AUTOSAR XML (schema 4-2-1)
standard types defined: boolean, float32, sint8, uint16, uint8, boolean_CompuMethod, boolean_DataConstr, float32_DataConstr, sint8_DataConstr, uint16_DataConstr, uint8_DataConstr
package /ComponentTypes
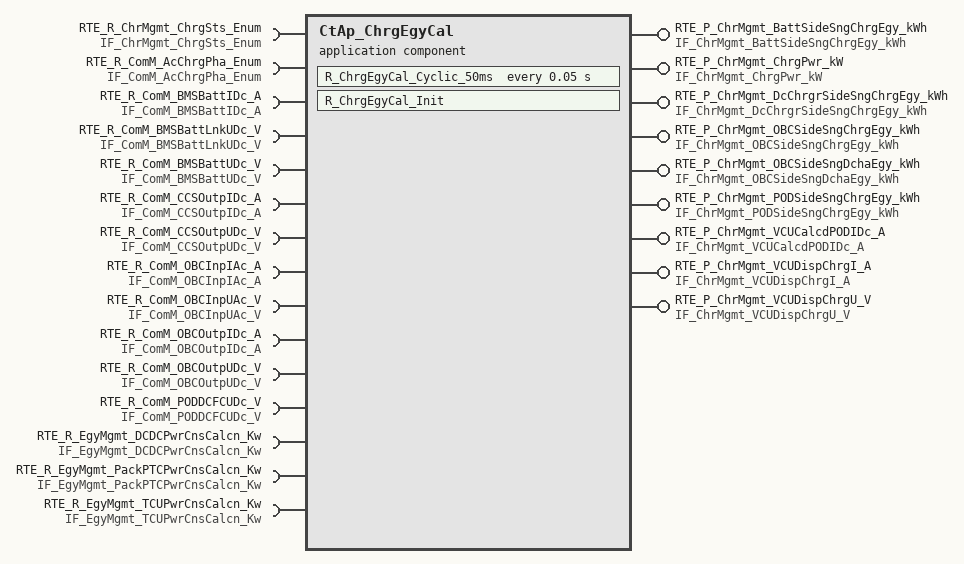
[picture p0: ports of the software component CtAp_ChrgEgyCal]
  application sw component type CtAp_ChrgEgyCal
    9 x provide port:
      RTE_P_ChrMgmt_BattSideSngChrgEgy_kWh: nonqueued-sender-com-spec{data-element=tec_ChrMgmt_BattSideSngChrgEgy_kWh, init-value=0}, provided-interface=IF_ChrMgmt_BattSideSngChrgEgy_kWh
      RTE_P_ChrMgmt_ChrgPwr_kW: nonqueued-sender-com-spec{data-element=tec_ChrMgmt_ChrgPwr_kW, init-value=0}, provided-interface=IF_ChrMgmt_ChrgPwr_kW
      RTE_P_ChrMgmt_DcChrgrSideSngChrgEgy_kWh: nonqueued-sender-com-spec{data-element=tec_ChrMgmt_DcChrgrSideSngChrgEgy_kWh, init-value=0}, provided-interface=IF_ChrMgmt_DcChrgrSideSngChrgEgy_kWh
      RTE_P_ChrMgmt_OBCSideSngChrgEgy_kWh: nonqueued-sender-com-spec{data-element=tec_ChrMgmt_OBCSideSngChrgEgy_kWh, init-value=0}, provided-interface=IF_ChrMgmt_OBCSideSngChrgEgy_kWh
      RTE_P_ChrMgmt_OBCSideSngDchaEgy_kWh: nonqueued-sender-com-spec{data-element=tec_ChrMgmt_OBCSideSngDchaEgy_kWh, init-value=0}, provided-interface=IF_ChrMgmt_OBCSideSngDchaEgy_kWh
      RTE_P_ChrMgmt_PODSideSngChrgEgy_kWh: nonqueued-sender-com-spec{data-element=tec_ChrMgmt_PODSideSngChrgEgy_kWh, init-value=0}, provided-interface=IF_ChrMgmt_PODSideSngChrgEgy_kWh
      RTE_P_ChrMgmt_VCUCalcdPODIDc_A: nonqueued-sender-com-spec{data-element=tec_ChrMgmt_VCUCalcdPODIDc_A, init-value=0}, provided-interface=IF_ChrMgmt_VCUCalcdPODIDc_A
      RTE_P_ChrMgmt_VCUDispChrgI_A: nonqueued-sender-com-spec{data-element=tec_ChrMgmt_VCUDispChrgI_A, init-value=0}, provided-interface=IF_ChrMgmt_VCUDispChrgI_A
      RTE_P_ChrMgmt_VCUDispChrgU_V: nonqueued-sender-com-spec{data-element=tec_ChrMgmt_VCUDispChrgU_V, init-value=0}, provided-interface=IF_ChrMgmt_VCUDispChrgU_V
    15 x require port:
      RTE_R_ChrMgmt_ChrgSts_Enum: nonqueued-receiver-com-spec{data-element=tec_ChrMgmt_ChrgSts_Enum, filter=data-filter-type=ALWAYS, init-value=0}, required-interface=IF_ChrMgmt_ChrgSts_Enum
      RTE_R_ComM_AcChrgPha_Enum: nonqueued-receiver-com-spec{data-element=tec_ComM_AcChrgPha_Enum, filter=data-filter-type=ALWAYS, init-value=0}, required-interface=IF_ComM_AcChrgPha_Enum
      RTE_R_ComM_BMSBattIDc_A: nonqueued-receiver-com-spec{data-element=tec_ComM_BMSBattIDc_A, filter=data-filter-type=ALWAYS, init-value=0}, required-interface=IF_ComM_BMSBattIDc_A
      RTE_R_ComM_BMSBattLnkUDc_V: nonqueued-receiver-com-spec{data-element=tec_ComM_BMSBattLnkUDc_V, filter=data-filter-type=ALWAYS, init-value=0}, required-interface=IF_ComM_BMSBattLnkUDc_V
      RTE_R_ComM_BMSBattUDc_V: nonqueued-receiver-com-spec{data-element=tec_ComM_BMSBattUDc_V, filter=data-filter-type=ALWAYS, init-value=0}, required-interface=IF_ComM_BMSBattUDc_V
      RTE_R_ComM_CCSOutpIDc_A: nonqueued-receiver-com-spec{data-element=tec_ComM_CCSOutpIDc_A, filter=data-filter-type=ALWAYS, init-value=0}, required-interface=IF_ComM_CCSOutpIDc_A
      RTE_R_ComM_CCSOutpUDc_V: nonqueued-receiver-com-spec{data-element=tec_ComM_CCSOutpUDc_V, filter=data-filter-type=ALWAYS, init-value=0}, required-interface=IF_ComM_CCSOutpUDc_V
      RTE_R_ComM_OBCInpIAc_A: nonqueued-receiver-com-spec{data-element=tec_ComM_OBCInpIAc_A, filter=data-filter-type=ALWAYS, init-value=0}, required-interface=IF_ComM_OBCInpIAc_A
      RTE_R_ComM_OBCInpUAc_V: nonqueued-receiver-com-spec{data-element=tec_ComM_OBCInpUAc_V, filter=data-filter-type=ALWAYS, init-value=0}, required-interface=IF_ComM_OBCInpUAc_V
      RTE_R_ComM_OBCOutpIDc_A: nonqueued-receiver-com-spec{data-element=tec_ComM_OBCOutpIDc_A, filter=data-filter-type=ALWAYS, init-value=0}, required-interface=IF_ComM_OBCOutpIDc_A
      RTE_R_ComM_OBCOutpUDc_V: nonqueued-receiver-com-spec{data-element=tec_ComM_OBCOutpUDc_V, filter=data-filter-type=ALWAYS, init-value=0}, required-interface=IF_ComM_OBCOutpUDc_V
      RTE_R_ComM_PODDCFCUDc_V: nonqueued-receiver-com-spec{data-element=tec_ComM_PODDCFCUDc_V, filter=data-filter-type=ALWAYS, init-value=0}, required-interface=IF_ComM_PODDCFCUDc_V
      RTE_R_EgyMgmt_DCDCPwrCnsCalcn_Kw: nonqueued-receiver-com-spec{data-element=tec_EgyMgmt_DCDCPwrCnsCalcn_Kw, filter=data-filter-type=ALWAYS, init-value=0}, required-interface=IF_EgyMgmt_DCDCPwrCnsCalcn_Kw
      RTE_R_EgyMgmt_PackPTCPwrCnsCalcn_Kw: nonqueued-receiver-com-spec{data-element=tec_EgyMgmt_PackPTCPwrCnsCalcn_Kw, filter=data-filter-type=ALWAYS, init-value=0}, required-interface=IF_EgyMgmt_PackPTCPwrCnsCalcn_Kw
      RTE_R_EgyMgmt_TCUPwrCnsCalcn_Kw: nonqueued-receiver-com-spec{data-element=tec_EgyMgmt_TCUPwrCnsCalcn_Kw, filter=data-filter-type=ALWAYS, init-value=0}, required-interface=IF_EgyMgmt_TCUPwrCnsCalcn_Kw
    behavior CtAp_ChrgEgyCal_InternalBehavior
      timing event TMT_R_ChrgEgyCal_Cyclic_50ms: start-on-event=R_ChrgEgyCal_Cyclic_50ms, period=0.05
      init event CtAp_ChrgEgyCal_InitEvent: start-on-event=R_ChrgEgyCal_Init
      runnable R_ChrgEgyCal_Cyclic_50ms
        data-receive-point-by-arguments:
          15 x access:
            REC_RTE_R_ChrMgmt_ChrgSts_Enum_tec_ChrMgmt_ChrgSts_Enum: accessed-variable=RTE_R_ChrMgmt_ChrgSts_Enum.tec_ChrMgmt_ChrgSts_Enum
            REC_RTE_R_ComM_AcChrgPha_Enum_tec_ComM_AcChrgPha_Enum: accessed-variable=RTE_R_ComM_AcChrgPha_Enum.tec_ComM_AcChrgPha_Enum
            REC_RTE_R_ComM_BMSBattIDc_A_tec_ComM_BMSBattIDc_A: accessed-variable=RTE_R_ComM_BMSBattIDc_A.tec_ComM_BMSBattIDc_A
            REC_RTE_R_ComM_BMSBattLnkUDc_V_tec_ComM_BMSBattLnkUDc_V: accessed-variable=RTE_R_ComM_BMSBattLnkUDc_V.tec_ComM_BMSBattLnkUDc_V
            REC_RTE_R_ComM_BMSBattUDc_V_tec_ComM_BMSBattUDc_V: accessed-variable=RTE_R_ComM_BMSBattUDc_V.tec_ComM_BMSBattUDc_V
            REC_RTE_R_ComM_CCSOutpIDc_A_tec_ComM_CCSOutpIDc_A: accessed-variable=RTE_R_ComM_CCSOutpIDc_A.tec_ComM_CCSOutpIDc_A
            REC_RTE_R_ComM_CCSOutpUDc_V_tec_ComM_CCSOutpUDc_V: accessed-variable=RTE_R_ComM_CCSOutpUDc_V.tec_ComM_CCSOutpUDc_V
            REC_RTE_R_ComM_OBCInpIAc_A_tec_ComM_OBCInpIAc_A: accessed-variable=RTE_R_ComM_OBCInpIAc_A.tec_ComM_OBCInpIAc_A
            REC_RTE_R_ComM_OBCInpUAc_V_tec_ComM_OBCInpUAc_V: accessed-variable=RTE_R_ComM_OBCInpUAc_V.tec_ComM_OBCInpUAc_V
            REC_RTE_R_ComM_OBCOutpIDc_A_tec_ComM_OBCOutpIDc_A: accessed-variable=RTE_R_ComM_OBCOutpIDc_A.tec_ComM_OBCOutpIDc_A
            REC_RTE_R_ComM_OBCOutpUDc_V_tec_ComM_OBCOutpUDc_V: accessed-variable=RTE_R_ComM_OBCOutpUDc_V.tec_ComM_OBCOutpUDc_V
            REC_RTE_R_ComM_PODDCFCUDc_V_tec_ComM_PODDCFCUDc_V: accessed-variable=RTE_R_ComM_PODDCFCUDc_V.tec_ComM_PODDCFCUDc_V
            REC_RTE_R_EgyMgmt_DCDCPwrCnsCalcn_Kw_tec_EgyMgmt_DCDCPwrCnsCalcn_Kw: accessed-variable=RTE_R_EgyMgmt_DCDCPwrCnsCalcn_Kw.tec_EgyMgmt_DCDCPwrCnsCalcn_Kw
            REC_RTE_R_EgyMgmt_PackPTCPwrCnsCalcn_Kw_tec_EgyMgmt_PackPTCPwrCnsCalcn_Kw: accessed-variable=RTE_R_EgyMgmt_PackPTCPwrCnsCalcn_Kw.tec_EgyMgmt_PackPTCPwrCnsCalcn_Kw
            REC_RTE_R_EgyMgmt_TCUPwrCnsCalcn_Kw_tec_EgyMgmt_TCUPwrCnsCalcn_Kw: accessed-variable=RTE_R_EgyMgmt_TCUPwrCnsCalcn_Kw.tec_EgyMgmt_TCUPwrCnsCalcn_Kw
        data-send-points:
          9 x access:
            SEND_RTE_P_ChrMgmt_BattSideSngChrgEgy_kWh_tec_ChrMgmt_BattSideSngChrgEgy_kWh: accessed-variable=RTE_P_ChrMgmt_BattSideSngChrgEgy_kWh.tec_ChrMgmt_BattSideSngChrgEgy_kWh
            SEND_RTE_P_ChrMgmt_ChrgPwr_kW_tec_ChrMgmt_ChrgPwr_kW: accessed-variable=RTE_P_ChrMgmt_ChrgPwr_kW.tec_ChrMgmt_ChrgPwr_kW
            SEND_RTE_P_ChrMgmt_DcChrgrSideSngChrgEgy_kWh_tec_ChrMgmt_DcChrgrSideSngChrgEgy_kWh: accessed-variable=RTE_P_ChrMgmt_DcChrgrSideSngChrgEgy_kWh.tec_ChrMgmt_DcChrgrSideSngChrgEgy_kWh
            SEND_RTE_P_ChrMgmt_OBCSideSngChrgEgy_kWh_tec_ChrMgmt_OBCSideSngChrgEgy_kWh: accessed-variable=RTE_P_ChrMgmt_OBCSideSngChrgEgy_kWh.tec_ChrMgmt_OBCSideSngChrgEgy_kWh
            SEND_RTE_P_ChrMgmt_OBCSideSngDchaEgy_kWh_tec_ChrMgmt_OBCSideSngDchaEgy_kWh: accessed-variable=RTE_P_ChrMgmt_OBCSideSngDchaEgy_kWh.tec_ChrMgmt_OBCSideSngDchaEgy_kWh
            SEND_RTE_P_ChrMgmt_PODSideSngChrgEgy_kWh_tec_ChrMgmt_PODSideSngChrgEgy_kWh: accessed-variable=RTE_P_ChrMgmt_PODSideSngChrgEgy_kWh.tec_ChrMgmt_PODSideSngChrgEgy_kWh
            SEND_RTE_P_ChrMgmt_VCUCalcdPODIDc_A_tec_ChrMgmt_VCUCalcdPODIDc_A: accessed-variable=RTE_P_ChrMgmt_VCUCalcdPODIDc_A.tec_ChrMgmt_VCUCalcdPODIDc_A
            SEND_RTE_P_ChrMgmt_VCUDispChrgI_A_tec_ChrMgmt_VCUDispChrgI_A: accessed-variable=RTE_P_ChrMgmt_VCUDispChrgI_A.tec_ChrMgmt_VCUDispChrgI_A
            SEND_RTE_P_ChrMgmt_VCUDispChrgU_V_tec_ChrMgmt_VCUDispChrgU_V: accessed-variable=RTE_P_ChrMgmt_VCUDispChrgU_V.tec_ChrMgmt_VCUDispChrgU_V
      runnable R_ChrgEgyCal_Init
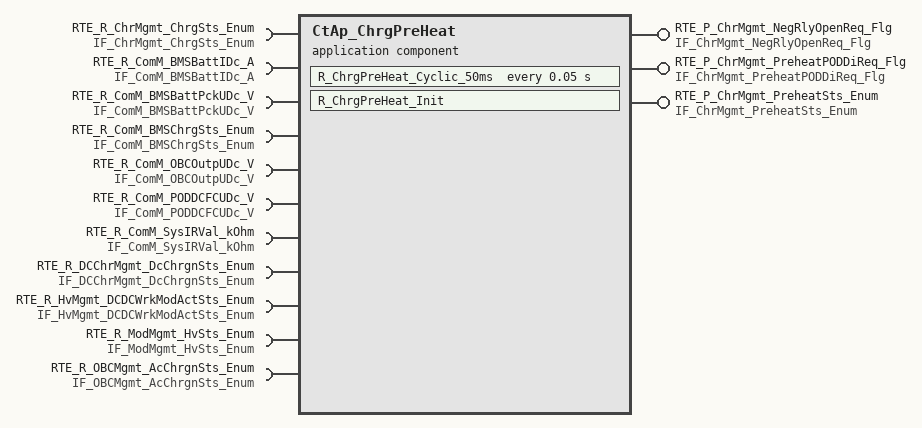
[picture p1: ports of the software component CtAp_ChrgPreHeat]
  application sw component type CtAp_ChrgPreHeat
    provide port RTE_P_ChrMgmt_NegRlyOpenReq_Flg: nonqueued-sender-com-spec{data-element=tec_ChrMgmt_NegRlyOpenReq_Flg, init-value=0}, provided-interface=IF_ChrMgmt_NegRlyOpenReq_Flg
    provide port RTE_P_ChrMgmt_PreheatPODDiReq_Flg: nonqueued-sender-com-spec{data-element=tec_ChrMgmt_PreheatPODDiReq_Flg, init-value=0}, provided-interface=IF_ChrMgmt_PreheatPODDiReq_Flg
    provide port RTE_P_ChrMgmt_PreheatSts_Enum: nonqueued-sender-com-spec{data-element=tec_ChrMgmt_PreheatSts_Enum, init-value=0}, provided-interface=IF_ChrMgmt_PreheatSts_Enum
    11 x require port:
      RTE_R_ChrMgmt_ChrgSts_Enum: nonqueued-receiver-com-spec{data-element=tec_ChrMgmt_ChrgSts_Enum, filter=data-filter-type=ALWAYS, init-value=0}, required-interface=IF_ChrMgmt_ChrgSts_Enum
      RTE_R_ComM_BMSBattIDc_A: nonqueued-receiver-com-spec{data-element=tec_ComM_BMSBattIDc_A, filter=data-filter-type=ALWAYS, init-value=0}, required-interface=IF_ComM_BMSBattIDc_A
      RTE_R_ComM_BMSBattPckUDc_V: nonqueued-receiver-com-spec{data-element=tec_ComM_BMSBattPckUDc_V, filter=data-filter-type=ALWAYS, init-value=0}, required-interface=IF_ComM_BMSBattPckUDc_V
      RTE_R_ComM_BMSChrgSts_Enum: nonqueued-receiver-com-spec{data-element=tec_ComM_BMSChrgSts_Enum, filter=data-filter-type=ALWAYS, init-value=0}, required-interface=IF_ComM_BMSChrgSts_Enum
      RTE_R_ComM_OBCOutpUDc_V: nonqueued-receiver-com-spec{data-element=tec_ComM_OBCOutpUDc_V, filter=data-filter-type=ALWAYS, init-value=0}, required-interface=IF_ComM_OBCOutpUDc_V
      RTE_R_ComM_PODDCFCUDc_V: nonqueued-receiver-com-spec{data-element=tec_ComM_PODDCFCUDc_V, filter=data-filter-type=ALWAYS, init-value=0}, required-interface=IF_ComM_PODDCFCUDc_V
      RTE_R_ComM_SysIRVal_kOhm: nonqueued-receiver-com-spec{data-element=tec_ComM_SysIRVal_kOhm, filter=data-filter-type=ALWAYS, init-value=0}, required-interface=IF_ComM_SysIRVal_kOhm
      RTE_R_DCChrMgmt_DcChrgnSts_Enum: nonqueued-receiver-com-spec{data-element=tec_DCChrMgmt_DcChrgnSts_Enum, filter=data-filter-type=ALWAYS, init-value=0}, required-interface=IF_DCChrMgmt_DcChrgnSts_Enum
      RTE_R_HvMgmt_DCDCWrkModActSts_Enum: nonqueued-receiver-com-spec{data-element=tec_HvMgmt_DCDCWrkModActSts_Enum, filter=data-filter-type=ALWAYS, init-value=0}, required-interface=IF_HvMgmt_DCDCWrkModActSts_Enum
      RTE_R_ModMgmt_HvSts_Enum: nonqueued-receiver-com-spec{data-element=tec_ModMgmt_HvSts_Enum, filter=data-filter-type=ALWAYS, init-value=0}, required-interface=IF_ModMgmt_HvSts_Enum
      RTE_R_OBCMgmt_AcChrgnSts_Enum: nonqueued-receiver-com-spec{data-element=tec_OBCMgmt_AcChrgnSts_Enum, filter=data-filter-type=ALWAYS, init-value=0}, required-interface=IF_OBCMgmt_AcChrgnSts_Enum
    behavior CtAp_ChrgPreHeat_InternalBehavior
      timing event TMT_R_ChrgPreHeat_Cyclic_50ms: start-on-event=R_ChrgPreHeat_Cyclic_50ms, period=0.05
      init event CtAp_ChrgPreHeat_InitEvent: start-on-event=R_ChrgPreHeat_Init
      runnable R_ChrgPreHeat_Cyclic_50ms
        data-receive-point-by-arguments:
          11 x access:
            REC_RTE_R_ChrMgmt_ChrgSts_Enum_tec_ChrMgmt_ChrgSts_Enum: accessed-variable=RTE_R_ChrMgmt_ChrgSts_Enum.tec_ChrMgmt_ChrgSts_Enum
            REC_RTE_R_ComM_BMSBattIDc_A_tec_ComM_BMSBattIDc_A: accessed-variable=RTE_R_ComM_BMSBattIDc_A.tec_ComM_BMSBattIDc_A
            REC_RTE_R_ComM_BMSBattPckUDc_V_tec_ComM_BMSBattPckUDc_V: accessed-variable=RTE_R_ComM_BMSBattPckUDc_V.tec_ComM_BMSBattPckUDc_V
            REC_RTE_R_ComM_BMSChrgSts_Enum_tec_ComM_BMSChrgSts_Enum: accessed-variable=RTE_R_ComM_BMSChrgSts_Enum.tec_ComM_BMSChrgSts_Enum
            REC_RTE_R_ComM_OBCOutpUDc_V_tec_ComM_OBCOutpUDc_V: accessed-variable=RTE_R_ComM_OBCOutpUDc_V.tec_ComM_OBCOutpUDc_V
            REC_RTE_R_ComM_PODDCFCUDc_V_tec_ComM_PODDCFCUDc_V: accessed-variable=RTE_R_ComM_PODDCFCUDc_V.tec_ComM_PODDCFCUDc_V
            REC_RTE_R_ComM_SysIRVal_kOhm_tec_ComM_SysIRVal_kOhm: accessed-variable=RTE_R_ComM_SysIRVal_kOhm.tec_ComM_SysIRVal_kOhm
            REC_RTE_R_DCChrMgmt_DcChrgnSts_Enum_tec_DCChrMgmt_DcChrgnSts_Enum: accessed-variable=RTE_R_DCChrMgmt_DcChrgnSts_Enum.tec_DCChrMgmt_DcChrgnSts_Enum
            REC_RTE_R_HvMgmt_DCDCWrkModActSts_Enum_tec_HvMgmt_DCDCWrkModActSts_Enum: accessed-variable=RTE_R_HvMgmt_DCDCWrkModActSts_Enum.tec_HvMgmt_DCDCWrkModActSts_Enum
            REC_RTE_R_ModMgmt_HvSts_Enum_tec_ModMgmt_HvSts_Enum: accessed-variable=RTE_R_ModMgmt_HvSts_Enum.tec_ModMgmt_HvSts_Enum
            REC_RTE_R_OBCMgmt_AcChrgnSts_Enum_tec_OBCMgmt_AcChrgnSts_Enum: accessed-variable=RTE_R_OBCMgmt_AcChrgnSts_Enum.tec_OBCMgmt_AcChrgnSts_Enum
        data-send-points:
          access SEND_RTE_P_ChrMgmt_NegRlyOpenReq_Flg_tec_ChrMgmt_NegRlyOpenReq_Flg: accessed-variable=RTE_P_ChrMgmt_NegRlyOpenReq_Flg.tec_ChrMgmt_NegRlyOpenReq_Flg
          access SEND_RTE_P_ChrMgmt_PreheatPODDiReq_Flg_tec_ChrMgmt_PreheatPODDiReq_Flg: accessed-variable=RTE_P_ChrMgmt_PreheatPODDiReq_Flg.tec_ChrMgmt_PreheatPODDiReq_Flg
          access SEND_RTE_P_ChrMgmt_PreheatSts_Enum_tec_ChrMgmt_PreheatSts_Enum: accessed-variable=RTE_P_ChrMgmt_PreheatSts_Enum.tec_ChrMgmt_PreheatSts_Enum
      runnable R_ChrgPreHeat_Init
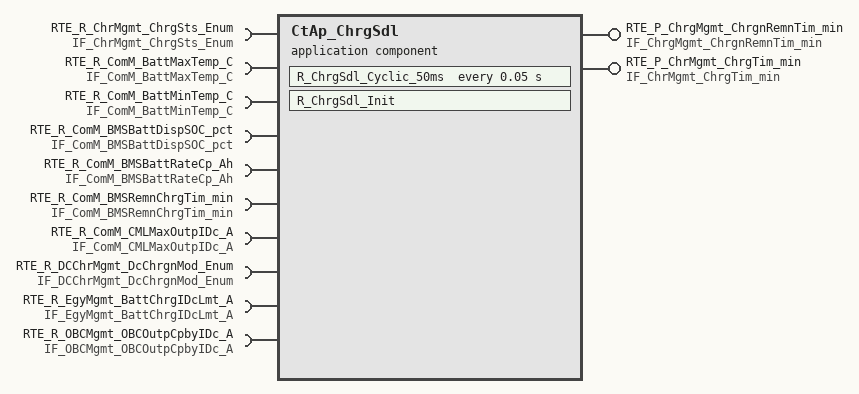
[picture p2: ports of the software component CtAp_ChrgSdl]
  application sw component type CtAp_ChrgSdl
    provide port RTE_P_ChrgMgmt_ChrgnRemnTim_min: nonqueued-sender-com-spec{data-element=tec_ChrgMgmt_ChrgnRemnTim_min, init-value=0}, provided-interface=IF_ChrgMgmt_ChrgnRemnTim_min
    provide port RTE_P_ChrMgmt_ChrgTim_min: nonqueued-sender-com-spec{data-element=tec_ChrMgmt_ChrgTim_min, init-value=0}, provided-interface=IF_ChrMgmt_ChrgTim_min
    10 x require port:
      RTE_R_ChrMgmt_ChrgSts_Enum: nonqueued-receiver-com-spec{data-element=tec_ChrMgmt_ChrgSts_Enum, filter=data-filter-type=ALWAYS, init-value=0}, required-interface=IF_ChrMgmt_ChrgSts_Enum
      RTE_R_ComM_BattMaxTemp_C: nonqueued-receiver-com-spec{data-element=tec_ComM_BMSBattMaxTemp_C, filter=data-filter-type=ALWAYS, init-value=0}, required-interface=IF_ComM_BattMaxTemp_C
      RTE_R_ComM_BattMinTemp_C: nonqueued-receiver-com-spec{data-element=tec_ComM_BMSBattMinTemp_C, filter=data-filter-type=ALWAYS, init-value=0}, required-interface=IF_ComM_BattMinTemp_C
      RTE_R_ComM_BMSBattDispSOC_pct: nonqueued-receiver-com-spec{data-element=tec_ComM_BMSBattDispSOC_pct, filter=data-filter-type=ALWAYS, init-value=0}, required-interface=IF_ComM_BMSBattDispSOC_pct
      RTE_R_ComM_BMSBattRateCp_Ah: nonqueued-receiver-com-spec{data-element=tec_ComM_BMSBattRateCp_Ah, filter=data-filter-type=ALWAYS, init-value=0}, required-interface=IF_ComM_BMSBattRateCp_Ah
      RTE_R_ComM_BMSRemnChrgTim_min: nonqueued-receiver-com-spec{data-element=tec_ComM_BMSRemnChrgTim_min, filter=data-filter-type=ALWAYS, init-value=0}, required-interface=IF_ComM_BMSRemnChrgTim_min
      RTE_R_ComM_CMLMaxOutpIDc_A: nonqueued-receiver-com-spec{data-element=tec_ComM_CMLMaxOutpIDc_A, filter=data-filter-type=ALWAYS, init-value=0}, required-interface=IF_ComM_CMLMaxOutpIDc_A
      RTE_R_DCChrMgmt_DcChrgnMod_Enum: nonqueued-receiver-com-spec{data-element=tec_DCChrMgmt_DcChrgnMod_Enum, filter=data-filter-type=ALWAYS, init-value=0}, required-interface=IF_DCChrMgmt_DcChrgnMod_Enum
      RTE_R_EgyMgmt_BattChrgIDcLmt_A: nonqueued-receiver-com-spec{data-element=tec_EgyMgmt_BattChrgIDcLmt_A, filter=data-filter-type=ALWAYS, init-value=0}, required-interface=IF_EgyMgmt_BattChrgIDcLmt_A
      RTE_R_OBCMgmt_OBCOutpCpbyIDc_A: nonqueued-receiver-com-spec{data-element=tec_OBCMgmt_OBCOutpCpbyIDc_A, filter=data-filter-type=ALWAYS, init-value=0}, required-interface=IF_OBCMgmt_OBCOutpCpbyIDc_A
    behavior CtAp_ChrgSdl_InternalBehavior
      timing event TMT_R_ChrgSdl_Cyclic_50ms: start-on-event=R_ChrgSdl_Cyclic_50ms, period=0.05
      init event CtAp_ChrgSdl_InitEvent: start-on-event=R_ChrgSdl_Init
      runnable R_ChrgSdl_Cyclic_50ms
        data-receive-point-by-arguments:
          10 x access:
            REC_RTE_R_ChrMgmt_ChrgSts_Enum_tec_ChrMgmt_ChrgSts_Enum: accessed-variable=RTE_R_ChrMgmt_ChrgSts_Enum.tec_ChrMgmt_ChrgSts_Enum
            REC_RTE_R_ComM_BattMaxTemp_C_tec_ComM_BMSBattMaxTemp_C: accessed-variable=RTE_R_ComM_BattMaxTemp_C.tec_ComM_BMSBattMaxTemp_C
            REC_RTE_R_ComM_BattMinTemp_C_tec_ComM_BMSBattMinTemp_C: accessed-variable=RTE_R_ComM_BattMinTemp_C.tec_ComM_BMSBattMinTemp_C
            REC_RTE_R_ComM_BMSBattDispSOC_pct_tec_ComM_BMSBattDispSOC_pct: accessed-variable=RTE_R_ComM_BMSBattDispSOC_pct.tec_ComM_BMSBattDispSOC_pct
            REC_RTE_R_ComM_BMSBattRateCp_Ah_tec_ComM_BMSBattRateCp_Ah: accessed-variable=RTE_R_ComM_BMSBattRateCp_Ah.tec_ComM_BMSBattRateCp_Ah
            REC_RTE_R_ComM_BMSRemnChrgTim_min_tec_ComM_BMSRemnChrgTim_min: accessed-variable=RTE_R_ComM_BMSRemnChrgTim_min.tec_ComM_BMSRemnChrgTim_min
            REC_RTE_R_ComM_CMLMaxOutpIDc_A_tec_ComM_CMLMaxOutpIDc_A: accessed-variable=RTE_R_ComM_CMLMaxOutpIDc_A.tec_ComM_CMLMaxOutpIDc_A
            REC_RTE_R_DCChrMgmt_DcChrgnMod_Enum_tec_DCChrMgmt_DcChrgnMod_Enum: accessed-variable=RTE_R_DCChrMgmt_DcChrgnMod_Enum.tec_DCChrMgmt_DcChrgnMod_Enum
            REC_RTE_R_EgyMgmt_BattChrgIDcLmt_A_tec_EgyMgmt_BattChrgIDcLmt_A: accessed-variable=RTE_R_EgyMgmt_BattChrgIDcLmt_A.tec_EgyMgmt_BattChrgIDcLmt_A
            REC_RTE_R_OBCMgmt_OBCOutpCpbyIDc_A_tec_OBCMgmt_OBCOutpCpbyIDc_A: accessed-variable=RTE_R_OBCMgmt_OBCOutpCpbyIDc_A.tec_OBCMgmt_OBCOutpCpbyIDc_A
        data-send-points:
          access SEND_RTE_P_ChrgMgmt_ChrgnRemnTim_min_tec_ChrgMgmt_ChrgnRemnTim_min: accessed-variable=RTE_P_ChrgMgmt_ChrgnRemnTim_min.tec_ChrgMgmt_ChrgnRemnTim_min
          access SEND_RTE_P_ChrMgmt_ChrgTim_min_tec_ChrMgmt_ChrgTim_min: accessed-variable=RTE_P_ChrMgmt_ChrgTim_min.tec_ChrMgmt_ChrgTim_min
      runnable R_ChrgSdl_Init
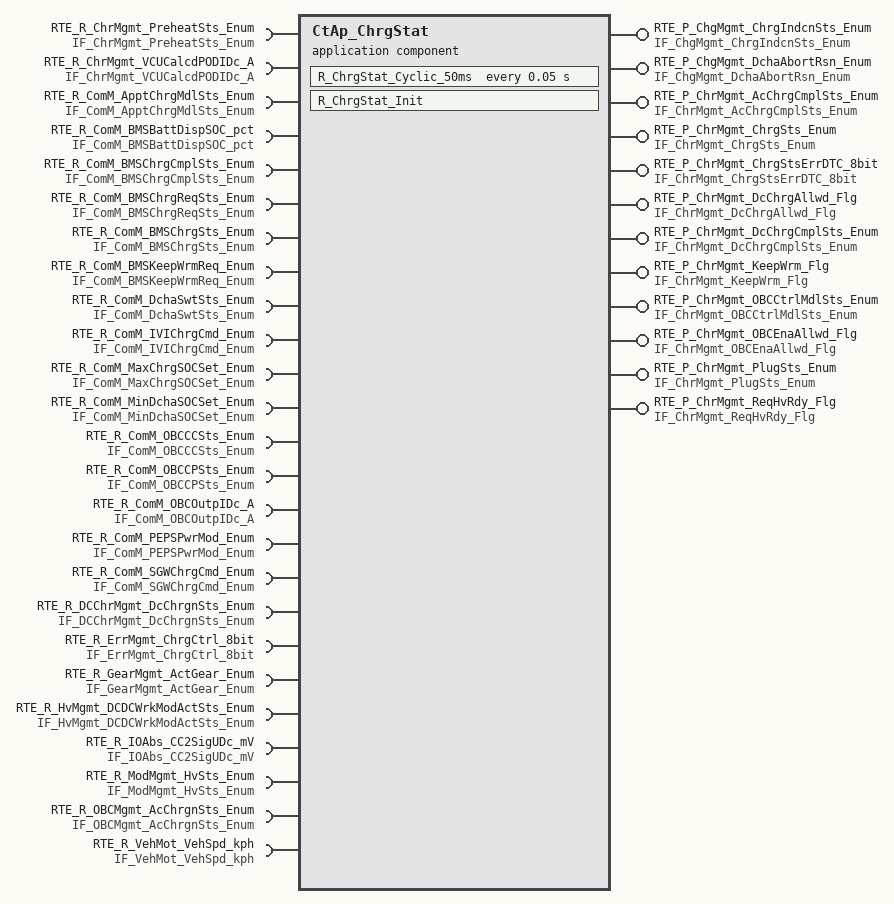
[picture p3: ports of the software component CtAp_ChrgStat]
  application sw component type CtAp_ChrgStat
    12 x provide port:
      RTE_P_ChgMgmt_ChrgIndcnSts_Enum: nonqueued-sender-com-spec{data-element=tec_ChgMgmt_ChrgIndcnSts_Enum, init-value=0}, provided-interface=IF_ChgMgmt_ChrgIndcnSts_Enum
      RTE_P_ChgMgmt_DchaAbortRsn_Enum: nonqueued-sender-com-spec{data-element=tec_ChgMgmt_DchaAbortRsn_Enum, init-value=0}, provided-interface=IF_ChgMgmt_DchaAbortRsn_Enum
      RTE_P_ChrMgmt_AcChrgCmplSts_Enum: nonqueued-sender-com-spec{data-element=tec_ChrMgmt_AcChrgCmplSts_Enum, init-value=0}, provided-interface=IF_ChrMgmt_AcChrgCmplSts_Enum
      RTE_P_ChrMgmt_ChrgSts_Enum: nonqueued-sender-com-spec{data-element=tec_ChrMgmt_ChrgSts_Enum, init-value=0}, provided-interface=IF_ChrMgmt_ChrgSts_Enum
      RTE_P_ChrMgmt_ChrgStsErrDTC_8bit: nonqueued-sender-com-spec{data-element=tec_ChrMgmt_ChrgStsErrDTC_8bit, init-value=0}, provided-interface=IF_ChrMgmt_ChrgStsErrDTC_8bit
      RTE_P_ChrMgmt_DcChrgAllwd_Flg: nonqueued-sender-com-spec{data-element=tec_ChrMgmt_DcChrgAllwd_Flg, init-value=0}, provided-interface=IF_ChrMgmt_DcChrgAllwd_Flg
      RTE_P_ChrMgmt_DcChrgCmplSts_Enum: nonqueued-sender-com-spec{data-element=tec_ChrMgmt_DcChrgCmplSts_Enum, init-value=0}, provided-interface=IF_ChrMgmt_DcChrgCmplSts_Enum
      RTE_P_ChrMgmt_KeepWrm_Flg: nonqueued-sender-com-spec{data-element=tec_ChrMgmt_KeepWrm_Flg, init-value=0}, provided-interface=IF_ChrMgmt_KeepWrm_Flg
      RTE_P_ChrMgmt_OBCCtrlMdlSts_Enum: nonqueued-sender-com-spec{data-element=tec_ChrMgmt_OBCCtrlMdlSts_Enum, init-value=0}, provided-interface=IF_ChrMgmt_OBCCtrlMdlSts_Enum
      RTE_P_ChrMgmt_OBCEnaAllwd_Flg: nonqueued-sender-com-spec{data-element=tec_ChrMgmt_OBCEnaAllwd_Flg, init-value=0}, provided-interface=IF_ChrMgmt_OBCEnaAllwd_Flg
      RTE_P_ChrMgmt_PlugSts_Enum: nonqueued-sender-com-spec{data-element=tec_ChrMgmt_PlugSts_Enum, init-value=0}, provided-interface=IF_ChrMgmt_PlugSts_Enum
      RTE_P_ChrMgmt_ReqHvRdy_Flg: nonqueued-sender-com-spec{data-element=tec_ChrMgmt_ReqHvRdy_Flg, init-value=0}, provided-interface=IF_ChrMgmt_ReqHvRdy_Flg
    25 x require port:
      RTE_R_ChrMgmt_PreheatSts_Enum: nonqueued-receiver-com-spec{data-element=tec_ChrMgmt_PreheatSts_Enum, filter=data-filter-type=ALWAYS, init-value=0}, required-interface=IF_ChrMgmt_PreheatSts_Enum
      RTE_R_ChrMgmt_VCUCalcdPODIDc_A: nonqueued-receiver-com-spec{data-element=tec_ChrMgmt_VCUCalcdPODIDc_A, filter=data-filter-type=ALWAYS, init-value=0}, required-interface=IF_ChrMgmt_VCUCalcdPODIDc_A
      RTE_R_ComM_ApptChrgMdlSts_Enum: nonqueued-receiver-com-spec{data-element=tec_ComM_ApptChrgMdlSts_Enum, filter=data-filter-type=ALWAYS, init-value=0}, required-interface=IF_ComM_ApptChrgMdlSts_Enum
      RTE_R_ComM_BMSBattDispSOC_pct: nonqueued-receiver-com-spec{data-element=tec_ComM_BMSBattDispSOC_pct, filter=data-filter-type=ALWAYS, init-value=0}, required-interface=IF_ComM_BMSBattDispSOC_pct
      RTE_R_ComM_BMSChrgCmplSts_Enum: nonqueued-receiver-com-spec{data-element=tec_ComM_BMSChrgCmplSts_Enum, filter=data-filter-type=ALWAYS, init-value=0}, required-interface=IF_ComM_BMSChrgCmplSts_Enum
      RTE_R_ComM_BMSChrgReqSts_Enum: nonqueued-receiver-com-spec{data-element=tec_ComM_BMSChrgReqSts_Enum, filter=data-filter-type=ALWAYS, init-value=0}, required-interface=IF_ComM_BMSChrgReqSts_Enum
      RTE_R_ComM_BMSChrgSts_Enum: nonqueued-receiver-com-spec{data-element=tec_ComM_BMSChrgSts_Enum, filter=data-filter-type=ALWAYS, init-value=0}, required-interface=IF_ComM_BMSChrgSts_Enum
      RTE_R_ComM_BMSKeepWrmReq_Enum: nonqueued-receiver-com-spec{data-element=tec_ComM_BMSKeepWrmReq_Enum, filter=data-filter-type=ALWAYS, init-value=0}, required-interface=IF_ComM_BMSKeepWrmReq_Enum
      RTE_R_ComM_DchaSwtSts_Enum: nonqueued-receiver-com-spec{data-element=tec_ComM_DchaSwtSts_Enum, filter=data-filter-type=ALWAYS, init-value=0}, required-interface=IF_ComM_DchaSwtSts_Enum
      RTE_R_ComM_IVIChrgCmd_Enum: nonqueued-receiver-com-spec{data-element=tec_ComM_IVIChrgCmd_Enum, filter=data-filter-type=ALWAYS, init-value=0}, required-interface=IF_ComM_IVIChrgCmd_Enum
      RTE_R_ComM_MaxChrgSOCSet_Enum: nonqueued-receiver-com-spec{data-element=tec_ComM_MaxChrgSOCSet_Enum, filter=data-filter-type=ALWAYS, init-value=0}, required-interface=IF_ComM_MaxChrgSOCSet_Enum
      RTE_R_ComM_MinDchaSOCSet_Enum: nonqueued-receiver-com-spec{data-element=tec_ComM_MinDchaSOCSet_Enum, filter=data-filter-type=ALWAYS, init-value=0}, required-interface=IF_ComM_MinDchaSOCSet_Enum
      RTE_R_ComM_OBCCCSts_Enum: nonqueued-receiver-com-spec{data-element=tec_ComM_OBCCCSts_Enum, filter=data-filter-type=ALWAYS, init-value=0}, required-interface=IF_ComM_OBCCCSts_Enum
      RTE_R_ComM_OBCCPSts_Enum: nonqueued-receiver-com-spec{data-element=tec_ComM_OBCCPSts_Enum, filter=data-filter-type=ALWAYS, init-value=0}, required-interface=IF_ComM_OBCCPSts_Enum
      RTE_R_ComM_OBCOutpIDc_A: nonqueued-receiver-com-spec{data-element=tec_ComM_OBCOutpIDc_A, filter=data-filter-type=ALWAYS, init-value=0}, required-interface=IF_ComM_OBCOutpIDc_A
      RTE_R_ComM_PEPSPwrMod_Enum: nonqueued-receiver-com-spec{data-element=tec_ComM_PEPSPwrMod_Enum, filter=data-filter-type=ALWAYS, init-value=0}, required-interface=IF_ComM_PEPSPwrMod_Enum
      RTE_R_ComM_SGWChrgCmd_Enum: nonqueued-receiver-com-spec{data-element=tec_ComM_SGWChrgCmd_Enum, filter=data-filter-type=ALWAYS, init-value=0}, required-interface=IF_ComM_SGWChrgCmd_Enum
      RTE_R_DCChrMgmt_DcChrgnSts_Enum: nonqueued-receiver-com-spec{data-element=tec_DCChrMgmt_DcChrgnSts_Enum, filter=data-filter-type=ALWAYS, init-value=0}, required-interface=IF_DCChrMgmt_DcChrgnSts_Enum
      RTE_R_ErrMgmt_ChrgCtrl_8bit: nonqueued-receiver-com-spec{data-element=tec_ErrMgmt_ChrgCtrl_8bit, filter=data-filter-type=ALWAYS, init-value=0}, required-interface=IF_ErrMgmt_ChrgCtrl_8bit
      RTE_R_GearMgmt_ActGear_Enum: nonqueued-receiver-com-spec{data-element=tec_GearMgmt_ActGear_Enum, filter=data-filter-type=ALWAYS, init-value=0}, required-interface=IF_GearMgmt_ActGear_Enum
      RTE_R_HvMgmt_DCDCWrkModActSts_Enum: nonqueued-receiver-com-spec{data-element=tec_HvMgmt_DCDCWrkModActSts_Enum, filter=data-filter-type=ALWAYS, init-value=0}, required-interface=IF_HvMgmt_DCDCWrkModActSts_Enum
      RTE_R_IOAbs_CC2SigUDc_mV: nonqueued-receiver-com-spec{data-element=tec_IOAbs_CC2SigUDc_mV, filter=data-filter-type=ALWAYS, init-value=0}, required-interface=IF_IOAbs_CC2SigUDc_mV
      RTE_R_ModMgmt_HvSts_Enum: nonqueued-receiver-com-spec{data-element=tec_ModMgmt_HvSts_Enum, filter=data-filter-type=ALWAYS, init-value=0}, required-interface=IF_ModMgmt_HvSts_Enum
      RTE_R_OBCMgmt_AcChrgnSts_Enum: nonqueued-receiver-com-spec{data-element=tec_OBCMgmt_AcChrgnSts_Enum, filter=data-filter-type=ALWAYS, init-value=0}, required-interface=IF_OBCMgmt_AcChrgnSts_Enum
      RTE_R_VehMot_VehSpd_kph: nonqueued-receiver-com-spec{data-element=tec_VehMot_VehSpd_kph, filter=data-filter-type=ALWAYS, init-value=0}, required-interface=IF_VehMot_VehSpd_kph
    behavior CtAp_ChrgStat_InternalBehavior
      timing event TMT_R_ChrgStat_Cyclic_50ms: start-on-event=R_ChrgStat_Cyclic_50ms, period=0.05
      init event CtAp_ChrgStat_InitEvent: start-on-event=R_ChrgStat_Init
      runnable R_ChrgStat_Cyclic_50ms
        data-receive-point-by-arguments:
          25 x access:
            REC_RTE_R_ChrMgmt_PreheatSts_Enum_tec_ChrMgmt_PreheatSts_Enum: accessed-variable=RTE_R_ChrMgmt_PreheatSts_Enum.tec_ChrMgmt_PreheatSts_Enum
            REC_RTE_R_ChrMgmt_VCUCalcdPODIDc_A_tec_ChrMgmt_VCUCalcdPODIDc_A: accessed-variable=RTE_R_ChrMgmt_VCUCalcdPODIDc_A.tec_ChrMgmt_VCUCalcdPODIDc_A
            REC_RTE_R_ComM_ApptChrgMdlSts_Enum_tec_ComM_ApptChrgMdlSts_Enum: accessed-variable=RTE_R_ComM_ApptChrgMdlSts_Enum.tec_ComM_ApptChrgMdlSts_Enum
            REC_RTE_R_ComM_BMSBattDispSOC_pct_tec_ComM_BMSBattDispSOC_pct: accessed-variable=RTE_R_ComM_BMSBattDispSOC_pct.tec_ComM_BMSBattDispSOC_pct
            REC_RTE_R_ComM_BMSChrgCmplSts_Enum_tec_ComM_BMSChrgCmplSts_Enum: accessed-variable=RTE_R_ComM_BMSChrgCmplSts_Enum.tec_ComM_BMSChrgCmplSts_Enum
            REC_RTE_R_ComM_BMSChrgReqSts_Enum_tec_ComM_BMSChrgReqSts_Enum: accessed-variable=RTE_R_ComM_BMSChrgReqSts_Enum.tec_ComM_BMSChrgReqSts_Enum
            REC_RTE_R_ComM_BMSChrgSts_Enum_tec_ComM_BMSChrgSts_Enum: accessed-variable=RTE_R_ComM_BMSChrgSts_Enum.tec_ComM_BMSChrgSts_Enum
            REC_RTE_R_ComM_BMSKeepWrmReq_Enum_tec_ComM_BMSKeepWrmReq_Enum: accessed-variable=RTE_R_ComM_BMSKeepWrmReq_Enum.tec_ComM_BMSKeepWrmReq_Enum
            REC_RTE_R_ComM_DchaSwtSts_Enum_tec_ComM_DchaSwtSts_Enum: accessed-variable=RTE_R_ComM_DchaSwtSts_Enum.tec_ComM_DchaSwtSts_Enum
            REC_RTE_R_ComM_IVIChrgCmd_Enum_tec_ComM_IVIChrgCmd_Enum: accessed-variable=RTE_R_ComM_IVIChrgCmd_Enum.tec_ComM_IVIChrgCmd_Enum
            REC_RTE_R_ComM_MaxChrgSOCSet_enum_tec_ComM_MaxChrgSOCSet_enum: accessed-variable=RTE_R_ComM_MaxChrgSOCSet_Enum.tec_ComM_MaxChrgSOCSet_Enum
            REC_RTE_R_ComM_MinDchaSOCSet_Enum_tec_ComM_MinDchaSOCSet_Enum: accessed-variable=RTE_R_ComM_MinDchaSOCSet_Enum.tec_ComM_MinDchaSOCSet_Enum
            REC_RTE_R_ComM_OBCCCSts_Enum_tec_ComM_OBCCCSts_Enum: accessed-variable=RTE_R_ComM_OBCCCSts_Enum.tec_ComM_OBCCCSts_Enum
            REC_RTE_R_ComM_OBCCPSts_Enum_tec_ComM_OBCCPSts_Enum: accessed-variable=RTE_R_ComM_OBCCPSts_Enum.tec_ComM_OBCCPSts_Enum
            REC_RTE_R_ComM_OBCOutpIDc_A_tec_ComM_OBCOutpIDc_A: accessed-variable=RTE_R_ComM_OBCOutpIDc_A.tec_ComM_OBCOutpIDc_A
            REC_RTE_R_ComM_PEPSPwrMod_Enum_tec_ComM_PEPSPwrMod_Enum: accessed-variable=RTE_R_ComM_PEPSPwrMod_Enum.tec_ComM_PEPSPwrMod_Enum
            REC_RTE_R_ComM_SGWChrgCmd_Enum_tec_ComM_SGWChrgCmd_Enum: accessed-variable=RTE_R_ComM_SGWChrgCmd_Enum.tec_ComM_SGWChrgCmd_Enum
            REC_RTE_R_DCChrMgmt_DcChrgnSts_Enum_tec_DCChrMgmt_DcChrgnSts_Enum: accessed-variable=RTE_R_DCChrMgmt_DcChrgnSts_Enum.tec_DCChrMgmt_DcChrgnSts_Enum
            REC_RTE_R_ErrMgmt_ChrgCtrl_8bit_tec_ErrMgmt_ChrgCtrl_8bit: accessed-variable=RTE_R_ErrMgmt_ChrgCtrl_8bit.tec_ErrMgmt_ChrgCtrl_8bit
            REC_RTE_R_GearMgmt_ActGear_Enum_tec_GearMgmt_ActGear_Enum: accessed-variable=RTE_R_GearMgmt_ActGear_Enum.tec_GearMgmt_ActGear_Enum
            REC_RTE_R_HvMgmt_DCDCWrkModActSts_Enum_tec_HvMgmt_DCDCWrkModActSts_Enum: accessed-variable=RTE_R_HvMgmt_DCDCWrkModActSts_Enum.tec_HvMgmt_DCDCWrkModActSts_Enum
            REC_RTE_R_IOAbs_CC2SigUDc_mV_tec_IOAbs_CC2SigUDc_mV: accessed-variable=RTE_R_IOAbs_CC2SigUDc_mV.tec_IOAbs_CC2SigUDc_mV
            REC_RTE_R_ModMgmt_HvSts_Enum_tec_ModMgmt_HvSts_Enum: accessed-variable=RTE_R_ModMgmt_HvSts_Enum.tec_ModMgmt_HvSts_Enum
            REC_RTE_R_OBCMgmt_AcChrgnSts_Enum_tec_OBCMgmt_AcChrgnSts_Enum: accessed-variable=RTE_R_OBCMgmt_AcChrgnSts_Enum.tec_OBCMgmt_AcChrgnSts_Enum
            REC_RTE_R_VehMot_VehSpd_kph_tec_VehMot_VehSpd_kph: accessed-variable=RTE_R_VehMot_VehSpd_kph.tec_VehMot_VehSpd_kph
        data-send-points:
          12 x access:
            SEND_RTE_P_ChgMgmt_ChrgIndcnSts_Enum_tec_ChgMgmt_ChrgIndcnSts_Enum: accessed-variable=RTE_P_ChgMgmt_ChrgIndcnSts_Enum.tec_ChgMgmt_ChrgIndcnSts_Enum
            SEND_RTE_P_ChgMgmt_DchaAbortRsn_Enum_tec_ChgMgmt_DchaAbortRsn_Enum: accessed-variable=RTE_P_ChgMgmt_DchaAbortRsn_Enum.tec_ChgMgmt_DchaAbortRsn_Enum
            SEND_RTE_P_ChrMgmt_AcChrgCmplSts_Enum_tec_ChrMgmt_AcChrgCmplSts_Enum: accessed-variable=RTE_P_ChrMgmt_AcChrgCmplSts_Enum.tec_ChrMgmt_AcChrgCmplSts_Enum
            SEND_RTE_P_ChrMgmt_ChrgSts_Enum_tec_ChrMgmt_ChrgSts_Enum: accessed-variable=RTE_P_ChrMgmt_ChrgSts_Enum.tec_ChrMgmt_ChrgSts_Enum
            SEND_RTE_P_ChrMgmt_ChrgStsErrDTC_8bit_tec_ChrMgmt_ChrgStsErrDTC_8bit: accessed-variable=RTE_P_ChrMgmt_ChrgStsErrDTC_8bit.tec_ChrMgmt_ChrgStsErrDTC_8bit
            SEND_RTE_P_ChrMgmt_DcChrgAllwd_Flg_tec_ChrMgmt_DcChrgAllwd_Flg: accessed-variable=RTE_P_ChrMgmt_DcChrgAllwd_Flg.tec_ChrMgmt_DcChrgAllwd_Flg
            SEND_RTE_P_ChrMgmt_DcChrgCmplSts_Enum_tec_ChrMgmt_DcChrgCmplSts_Enu: accessed-variable=RTE_P_ChrMgmt_DcChrgCmplSts_Enum.tec_ChrMgmt_DcChrgCmplSts_Enum
            SEND_RTE_P_ChrMgmt_KeepWrm_Flg_tec_ChrMgmt_KeepWrm_Flg: accessed-variable=RTE_P_ChrMgmt_KeepWrm_Flg.tec_ChrMgmt_KeepWrm_Flg
            SEND_RTE_P_ChrMgmt_OBCCtrlMdlSts_Enum_tec_ChrMgmt_OBCCtrlMdlSts_Enum: accessed-variable=RTE_P_ChrMgmt_OBCCtrlMdlSts_Enum.tec_ChrMgmt_OBCCtrlMdlSts_Enum
            SEND_RTE_P_ChrMgmt_OBCEnaAllwd_Flg_tec_ChrMgmt_OBCEnaAllwd_Flg: accessed-variable=RTE_P_ChrMgmt_OBCEnaAllwd_Flg.tec_ChrMgmt_OBCEnaAllwd_Flg
            SEND_RTE_P_ChrMgmt_PlugSts_Enum_tec_ChrMgmt_PlugSts_Enum: accessed-variable=RTE_P_ChrMgmt_PlugSts_Enum.tec_ChrMgmt_PlugSts_Enum
            SEND_RTE_P_ChrMgmt_ReqHvRdy_Flg_tec_ChrMgmt_ReqHvRdy_Flg: accessed-variable=RTE_P_ChrMgmt_ReqHvRdy_Flg.tec_ChrMgmt_ReqHvRdy_Flg
      runnable R_ChrgStat_Init
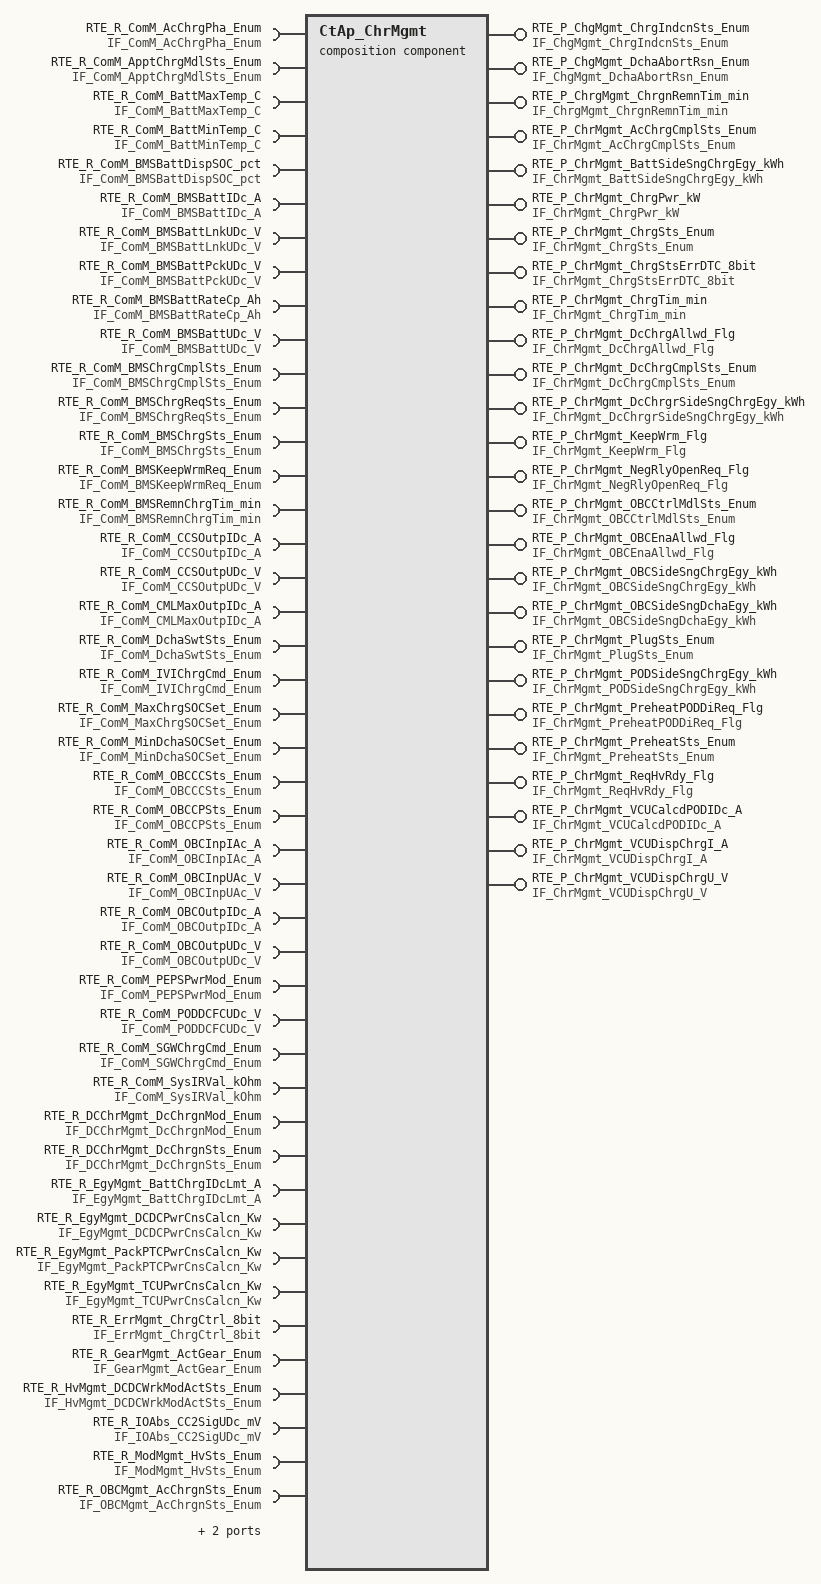
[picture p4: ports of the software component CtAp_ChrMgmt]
  composition sw component type CtAp_ChrMgmt
    26 x provide port:
      RTE_P_ChgMgmt_ChrgIndcnSts_Enum: nonqueued-sender-com-spec{data-element=tec_ChgMgmt_ChrgIndcnSts_Enum, init-value=0}, provided-interface=IF_ChgMgmt_ChrgIndcnSts_Enum
      RTE_P_ChgMgmt_DchaAbortRsn_Enum: nonqueued-sender-com-spec{data-element=tec_ChgMgmt_DchaAbortRsn_Enum, init-value=0}, provided-interface=IF_ChgMgmt_DchaAbortRsn_Enum
      RTE_P_ChrgMgmt_ChrgnRemnTim_min: nonqueued-sender-com-spec{data-element=tec_ChrgMgmt_ChrgnRemnTim_min, init-value=0}, provided-interface=IF_ChrgMgmt_ChrgnRemnTim_min
      RTE_P_ChrMgmt_AcChrgCmplSts_Enum: nonqueued-sender-com-spec{data-element=tec_ChrMgmt_AcChrgCmplSts_Enum, init-value=0}, provided-interface=IF_ChrMgmt_AcChrgCmplSts_Enum
      RTE_P_ChrMgmt_BattSideSngChrgEgy_kWh: nonqueued-sender-com-spec{data-element=tec_ChrMgmt_BattSideSngChrgEgy_kWh, init-value=0}, provided-interface=IF_ChrMgmt_BattSideSngChrgEgy_kWh
      RTE_P_ChrMgmt_ChrgPwr_kW: nonqueued-sender-com-spec{data-element=tec_ChrMgmt_ChrgPwr_kW, init-value=0}, provided-interface=IF_ChrMgmt_ChrgPwr_kW
      RTE_P_ChrMgmt_ChrgSts_Enum: nonqueued-sender-com-spec{data-element=tec_ChrMgmt_ChrgSts_Enum, init-value=0}, provided-interface=IF_ChrMgmt_ChrgSts_Enum
      RTE_P_ChrMgmt_ChrgStsErrDTC_8bit: nonqueued-sender-com-spec{data-element=tec_ChrMgmt_ChrgStsErrDTC_8bit, init-value=0}, provided-interface=IF_ChrMgmt_ChrgStsErrDTC_8bit
      RTE_P_ChrMgmt_ChrgTim_min: nonqueued-sender-com-spec{data-element=tec_ChrMgmt_ChrgTim_min, init-value=0}, provided-interface=IF_ChrMgmt_ChrgTim_min
      RTE_P_ChrMgmt_DcChrgAllwd_Flg: nonqueued-sender-com-spec{data-element=tec_ChrMgmt_DcChrgAllwd_Flg, init-value=0}, provided-interface=IF_ChrMgmt_DcChrgAllwd_Flg
      RTE_P_ChrMgmt_DcChrgCmplSts_Enum: nonqueued-sender-com-spec{data-element=tec_ChrMgmt_DcChrgCmplSts_Enum, init-value=0}, provided-interface=IF_ChrMgmt_DcChrgCmplSts_Enum
      RTE_P_ChrMgmt_DcChrgrSideSngChrgEgy_kWh: nonqueued-sender-com-spec{data-element=tec_ChrMgmt_DcChrgrSideSngChrgEgy_kWh, init-value=0}, provided-interface=IF_ChrMgmt_DcChrgrSideSngChrgEgy_kWh
      RTE_P_ChrMgmt_KeepWrm_Flg: nonqueued-sender-com-spec{data-element=tec_ChrMgmt_KeepWrm_Flg, init-value=0}, provided-interface=IF_ChrMgmt_KeepWrm_Flg
      RTE_P_ChrMgmt_NegRlyOpenReq_Flg: nonqueued-sender-com-spec{data-element=tec_ChrMgmt_NegRlyOpenReq_Flg, init-value=0}, provided-interface=IF_ChrMgmt_NegRlyOpenReq_Flg
      RTE_P_ChrMgmt_OBCCtrlMdlSts_Enum: nonqueued-sender-com-spec{data-element=tec_ChrMgmt_OBCCtrlMdlSts_Enum, init-value=0}, provided-interface=IF_ChrMgmt_OBCCtrlMdlSts_Enum
      RTE_P_ChrMgmt_OBCEnaAllwd_Flg: nonqueued-sender-com-spec{data-element=tec_ChrMgmt_OBCEnaAllwd_Flg, init-value=0}, provided-interface=IF_ChrMgmt_OBCEnaAllwd_Flg
      RTE_P_ChrMgmt_OBCSideSngChrgEgy_kWh: nonqueued-sender-com-spec{data-element=tec_ChrMgmt_OBCSideSngChrgEgy_kWh, init-value=0}, provided-interface=IF_ChrMgmt_OBCSideSngChrgEgy_kWh
      RTE_P_ChrMgmt_OBCSideSngDchaEgy_kWh: nonqueued-sender-com-spec{data-element=tec_ChrMgmt_OBCSideSngDchaEgy_kWh, init-value=0}, provided-interface=IF_ChrMgmt_OBCSideSngDchaEgy_kWh
      RTE_P_ChrMgmt_PlugSts_Enum: nonqueued-sender-com-spec{data-element=tec_ChrMgmt_PlugSts_Enum, init-value=0}, provided-interface=IF_ChrMgmt_PlugSts_Enum
      RTE_P_ChrMgmt_PODSideSngChrgEgy_kWh: nonqueued-sender-com-spec{data-element=tec_ChrMgmt_PODSideSngChrgEgy_kWh, init-value=0}, provided-interface=IF_ChrMgmt_PODSideSngChrgEgy_kWh
      RTE_P_ChrMgmt_PreheatPODDiReq_Flg: nonqueued-sender-com-spec{data-element=tec_ChrMgmt_PreheatPODDiReq_Flg, init-value=0}, provided-interface=IF_ChrMgmt_PreheatPODDiReq_Flg
      RTE_P_ChrMgmt_PreheatSts_Enum: nonqueued-sender-com-spec{data-element=tec_ChrMgmt_PreheatSts_Enum, init-value=0}, provided-interface=IF_ChrMgmt_PreheatSts_Enum
      RTE_P_ChrMgmt_ReqHvRdy_Flg: nonqueued-sender-com-spec{data-element=tec_ChrMgmt_ReqHvRdy_Flg, init-value=0}, provided-interface=IF_ChrMgmt_ReqHvRdy_Flg
      RTE_P_ChrMgmt_VCUCalcdPODIDc_A: nonqueued-sender-com-spec{data-element=tec_ChrMgmt_VCUCalcdPODIDc_A, init-value=0}, provided-interface=IF_ChrMgmt_VCUCalcdPODIDc_A
      RTE_P_ChrMgmt_VCUDispChrgI_A: nonqueued-sender-com-spec{data-element=tec_ChrMgmt_VCUDispChrgI_A, init-value=0}, provided-interface=IF_ChrMgmt_VCUDispChrgI_A
      RTE_P_ChrMgmt_VCUDispChrgU_V: nonqueued-sender-com-spec{data-element=tec_ChrMgmt_VCUDispChrgU_V, init-value=0}, provided-interface=IF_ChrMgmt_VCUDispChrgU_V
    46 x require port:
      RTE_R_ComM_AcChrgPha_Enum: nonqueued-receiver-com-spec{data-element=tec_ComM_AcChrgPha_Enum, filter=data-filter-type=ALWAYS, init-value=0}, required-interface=IF_ComM_AcChrgPha_Enum
      RTE_R_ComM_ApptChrgMdlSts_Enum: nonqueued-receiver-com-spec{data-element=tec_ComM_ApptChrgMdlSts_Enum, filter=data-filter-type=ALWAYS, init-value=0}, required-interface=IF_ComM_ApptChrgMdlSts_Enum
      RTE_R_ComM_BattMaxTemp_C: nonqueued-receiver-com-spec{data-element=tec_ComM_BMSBattMaxTemp_C, filter=data-filter-type=ALWAYS, init-value=0}, required-interface=IF_ComM_BattMaxTemp_C
      RTE_R_ComM_BattMinTemp_C: nonqueued-receiver-com-spec{data-element=tec_ComM_BMSBattMinTemp_C, filter=data-filter-type=ALWAYS, init-value=0}, required-interface=IF_ComM_BattMinTemp_C
      RTE_R_ComM_BMSBattDispSOC_pct: nonqueued-receiver-com-spec{data-element=tec_ComM_BMSBattDispSOC_pct, filter=data-filter-type=ALWAYS, init-value=0}, required-interface=IF_ComM_BMSBattDispSOC_pct
      RTE_R_ComM_BMSBattIDc_A: nonqueued-receiver-com-spec{data-element=tec_ComM_BMSBattIDc_A, filter=data-filter-type=ALWAYS, init-value=0}, required-interface=IF_ComM_BMSBattIDc_A
      RTE_R_ComM_BMSBattLnkUDc_V: nonqueued-receiver-com-spec{data-element=tec_ComM_BMSBattLnkUDc_V, filter=data-filter-type=ALWAYS, init-value=0}, required-interface=IF_ComM_BMSBattLnkUDc_V
      RTE_R_ComM_BMSBattPckUDc_V: nonqueued-receiver-com-spec{data-element=tec_ComM_BMSBattPckUDc_V, filter=data-filter-type=ALWAYS, init-value=0}, required-interface=IF_ComM_BMSBattPckUDc_V
      RTE_R_ComM_BMSBattRateCp_Ah: nonqueued-receiver-com-spec{data-element=tec_ComM_BMSBattRateCp_Ah, filter=data-filter-type=ALWAYS, init-value=0}, required-interface=IF_ComM_BMSBattRateCp_Ah
      RTE_R_ComM_BMSBattUDc_V: nonqueued-receiver-com-spec{data-element=tec_ComM_BMSBattUDc_V, filter=data-filter-type=ALWAYS, init-value=0}, required-interface=IF_ComM_BMSBattUDc_V
      RTE_R_ComM_BMSChrgCmplSts_Enum: nonqueued-receiver-com-spec{data-element=tec_ComM_BMSChrgCmplSts_Enum, filter=data-filter-type=ALWAYS, init-value=0}, required-interface=IF_ComM_BMSChrgCmplSts_Enum
      RTE_R_ComM_BMSChrgReqSts_Enum: nonqueued-receiver-com-spec{data-element=tec_ComM_BMSChrgReqSts_Enum, filter=data-filter-type=ALWAYS, init-value=0}, required-interface=IF_ComM_BMSChrgReqSts_Enum
      RTE_R_ComM_BMSChrgSts_Enum: nonqueued-receiver-com-spec{data-element=tec_ComM_BMSChrgSts_Enum, filter=data-filter-type=ALWAYS, init-value=0}, required-interface=IF_ComM_BMSChrgSts_Enum
      RTE_R_ComM_BMSKeepWrmReq_Enum: nonqueued-receiver-com-spec{data-element=tec_ComM_BMSKeepWrmReq_Enum, filter=data-filter-type=ALWAYS, init-value=0}, required-interface=IF_ComM_BMSKeepWrmReq_Enum
      RTE_R_ComM_BMSRemnChrgTim_min: nonqueued-receiver-com-spec{data-element=tec_ComM_BMSRemnChrgTim_min, filter=data-filter-type=ALWAYS, init-value=0}, required-interface=IF_ComM_BMSRemnChrgTim_min
      RTE_R_ComM_CCSOutpIDc_A: nonqueued-receiver-com-spec{data-element=tec_ComM_CCSOutpIDc_A, filter=data-filter-type=ALWAYS, init-value=0}, required-interface=IF_ComM_CCSOutpIDc_A
      RTE_R_ComM_CCSOutpUDc_V: nonqueued-receiver-com-spec{data-element=tec_ComM_CCSOutpUDc_V, filter=data-filter-type=ALWAYS, init-value=0}, required-interface=IF_ComM_CCSOutpUDc_V
      RTE_R_ComM_CMLMaxOutpIDc_A: nonqueued-receiver-com-spec{data-element=tec_ComM_CMLMaxOutpIDc_A, filter=data-filter-type=ALWAYS, init-value=0}, required-interface=IF_ComM_CMLMaxOutpIDc_A
      RTE_R_ComM_DchaSwtSts_Enum: nonqueued-receiver-com-spec{data-element=tec_ComM_DchaSwtSts_Enum, filter=data-filter-type=ALWAYS, init-value=0}, required-interface=IF_ComM_DchaSwtSts_Enum
      RTE_R_ComM_IVIChrgCmd_Enum: nonqueued-receiver-com-spec{data-element=tec_ComM_IVIChrgCmd_Enum, filter=data-filter-type=ALWAYS, init-value=0}, required-interface=IF_ComM_IVIChrgCmd_Enum
      RTE_R_ComM_MaxChrgSOCSet_Enum: nonqueued-receiver-com-spec{data-element=tec_ComM_MaxChrgSOCSet_Enum, filter=data-filter-type=ALWAYS, init-value=0}, required-interface=IF_ComM_MaxChrgSOCSet_Enum
      RTE_R_ComM_MinDchaSOCSet_Enum: nonqueued-receiver-com-spec{data-element=tec_ComM_MinDchaSOCSet_Enum, filter=data-filter-type=ALWAYS, init-value=0}, required-interface=IF_ComM_MinDchaSOCSet_Enum
      RTE_R_ComM_OBCCCSts_Enum: nonqueued-receiver-com-spec{data-element=tec_ComM_OBCCCSts_Enum, filter=data-filter-type=ALWAYS, init-value=0}, required-interface=IF_ComM_OBCCCSts_Enum
      RTE_R_ComM_OBCCPSts_Enum: nonqueued-receiver-com-spec{data-element=tec_ComM_OBCCPSts_Enum, filter=data-filter-type=ALWAYS, init-value=0}, required-interface=IF_ComM_OBCCPSts_Enum
      RTE_R_ComM_OBCInpIAc_A: nonqueued-receiver-com-spec{data-element=tec_ComM_OBCInpIAc_A, filter=data-filter-type=ALWAYS, init-value=0}, required-interface=IF_ComM_OBCInpIAc_A
      RTE_R_ComM_OBCInpUAc_V: nonqueued-receiver-com-spec{data-element=tec_ComM_OBCInpUAc_V, filter=data-filter-type=ALWAYS, init-value=0}, required-interface=IF_ComM_OBCInpUAc_V
      RTE_R_ComM_OBCOutpIDc_A: nonqueued-receiver-com-spec{data-element=tec_ComM_OBCOutpIDc_A, filter=data-filter-type=ALWAYS, init-value=0}, required-interface=IF_ComM_OBCOutpIDc_A
      RTE_R_ComM_OBCOutpUDc_V: nonqueued-receiver-com-spec{data-element=tec_ComM_OBCOutpUDc_V, filter=data-filter-type=ALWAYS, init-value=0}, required-interface=IF_ComM_OBCOutpUDc_V
      RTE_R_ComM_PEPSPwrMod_Enum: nonqueued-receiver-com-spec{data-element=tec_ComM_PEPSPwrMod_Enum, filter=data-filter-type=ALWAYS, init-value=0}, required-interface=IF_ComM_PEPSPwrMod_Enum
      RTE_R_ComM_PODDCFCUDc_V: nonqueued-receiver-com-spec{data-element=tec_ComM_PODDCFCUDc_V, filter=data-filter-type=ALWAYS, init-value=0}, required-interface=IF_ComM_PODDCFCUDc_V
      RTE_R_ComM_SGWChrgCmd_Enum: nonqueued-receiver-com-spec{data-element=tec_ComM_SGWChrgCmd_Enum, filter=data-filter-type=ALWAYS, init-value=0}, required-interface=IF_ComM_SGWChrgCmd_Enum
      RTE_R_ComM_SysIRVal_kOhm: nonqueued-receiver-com-spec{data-element=tec_ComM_SysIRVal_kOhm, filter=data-filter-type=ALWAYS, init-value=0}, required-interface=IF_ComM_SysIRVal_kOhm
      RTE_R_DCChrMgmt_DcChrgnMod_Enum: nonqueued-receiver-com-spec{data-element=tec_DCChrMgmt_DcChrgnMod_Enum, filter=data-filter-type=ALWAYS, init-value=0}, required-interface=IF_DCChrMgmt_DcChrgnMod_Enum
      RTE_R_DCChrMgmt_DcChrgnSts_Enum: nonqueued-receiver-com-spec{data-element=tec_DCChrMgmt_DcChrgnSts_Enum, filter=data-filter-type=ALWAYS, init-value=0}, required-interface=IF_DCChrMgmt_DcChrgnSts_Enum
      RTE_R_EgyMgmt_BattChrgIDcLmt_A: nonqueued-receiver-com-spec{data-element=tec_EgyMgmt_BattChrgIDcLmt_A, filter=data-filter-type=ALWAYS, init-value=0}, required-interface=IF_EgyMgmt_BattChrgIDcLmt_A
      RTE_R_EgyMgmt_DCDCPwrCnsCalcn_Kw: nonqueued-receiver-com-spec{data-element=tec_EgyMgmt_DCDCPwrCnsCalcn_Kw, filter=data-filter-type=ALWAYS, init-value=0}, required-interface=IF_EgyMgmt_DCDCPwrCnsCalcn_Kw
      RTE_R_EgyMgmt_PackPTCPwrCnsCalcn_Kw: nonqueued-receiver-com-spec{data-element=tec_EgyMgmt_PackPTCPwrCnsCalcn_Kw, filter=data-filter-type=ALWAYS, init-value=0}, required-interface=IF_EgyMgmt_PackPTCPwrCnsCalcn_Kw
      RTE_R_EgyMgmt_TCUPwrCnsCalcn_Kw: nonqueued-receiver-com-spec{data-element=tec_EgyMgmt_TCUPwrCnsCalcn_Kw, filter=data-filter-type=ALWAYS, init-value=0}, required-interface=IF_EgyMgmt_TCUPwrCnsCalcn_Kw
      RTE_R_ErrMgmt_ChrgCtrl_8bit: nonqueued-receiver-com-spec{data-element=tec_ErrMgmt_ChrgCtrl_8bit, filter=data-filter-type=ALWAYS, init-value=0}, required-interface=IF_ErrMgmt_ChrgCtrl_8bit
      RTE_R_GearMgmt_ActGear_Enum: nonqueued-receiver-com-spec{data-element=tec_GearMgmt_ActGear_Enum, filter=data-filter-type=ALWAYS, init-value=0}, required-interface=IF_GearMgmt_ActGear_Enum
      RTE_R_HvMgmt_DCDCWrkModActSts_Enum: nonqueued-receiver-com-spec{data-element=tec_HvMgmt_DCDCWrkModActSts_Enum, filter=data-filter-type=ALWAYS, init-value=0}, required-interface=IF_HvMgmt_DCDCWrkModActSts_Enum
      RTE_R_IOAbs_CC2SigUDc_mV: nonqueued-receiver-com-spec{data-element=tec_IOAbs_CC2SigUDc_mV, filter=data-filter-type=ALWAYS, init-value=0}, required-interface=IF_IOAbs_CC2SigUDc_mV
      RTE_R_ModMgmt_HvSts_Enum: nonqueued-receiver-com-spec{data-element=tec_ModMgmt_HvSts_Enum, filter=data-filter-type=ALWAYS, init-value=0}, required-interface=IF_ModMgmt_HvSts_Enum
      RTE_R_OBCMgmt_AcChrgnSts_Enum: nonqueued-receiver-com-spec{data-element=tec_OBCMgmt_AcChrgnSts_Enum, filter=data-filter-type=ALWAYS, init-value=0}, required-interface=IF_OBCMgmt_AcChrgnSts_Enum
      RTE_R_OBCMgmt_OBCOutpCpbyIDc_A: nonqueued-receiver-com-spec{data-element=tec_OBCMgmt_OBCOutpCpbyIDc_A, filter=data-filter-type=ALWAYS, init-value=0}, required-interface=IF_OBCMgmt_OBCOutpCpbyIDc_A
      RTE_R_VehMot_VehSpd_kph: nonqueued-receiver-com-spec{data-element=tec_VehMot_VehSpd_kph, filter=data-filter-type=ALWAYS, init-value=0}, required-interface=IF_VehMot_VehSpd_kph
    4 x component:
      CtAp_ChrgEgyCal: type=CtAp_ChrgEgyCal
      CtAp_ChrgPreHeat: type=CtAp_ChrgPreHeat
      CtAp_ChrgSdl: type=CtAp_ChrgSdl
      CtAp_ChrgStat: type=CtAp_ChrgStat
    connect CtAp_ChrgEgyCal.RTE_P_ChrMgmt_VCUCalcdPODIDc_A -> CtAp_ChrgStat.RTE_R_ChrMgmt_VCUCalcdPODIDc_A
    connect CtAp_ChrgPreHeat.RTE_P_ChrMgmt_PreheatSts_Enum -> CtAp_ChrgStat.RTE_R_ChrMgmt_PreheatSts_Enum
    connect CtAp_ChrgStat.RTE_P_ChrMgmt_ChrgSts_Enum -> CtAp_ChrgEgyCal.RTE_R_ChrMgmt_ChrgSts_Enum
    connect CtAp_ChrgStat.RTE_P_ChrMgmt_ChrgSts_Enum -> CtAp_ChrgPreHeat.RTE_R_ChrMgmt_ChrgSts_Enum
    connect CtAp_ChrgStat.RTE_P_ChrMgmt_ChrgSts_Enum -> CtAp_ChrgSdl.RTE_R_ChrMgmt_ChrgSts_Enum
    delegate CtAp_ChrgStat.RTE_P_ChgMgmt_ChrgIndcnSts_Enum <-> outer port CtAp_ChrMgmt/RTE_P_ChgMgmt_ChrgIndcnSts_Enum
    delegate CtAp_ChrgStat.RTE_P_ChgMgmt_DchaAbortRsn_Enum <-> outer port CtAp_ChrMgmt/RTE_P_ChgMgmt_DchaAbortRsn_Enum
    delegate CtAp_ChrgSdl.RTE_P_ChrgMgmt_ChrgnRemnTim_min <-> outer port CtAp_ChrMgmt/RTE_P_ChrgMgmt_ChrgnRemnTim_min
    delegate CtAp_ChrgStat.RTE_P_ChrMgmt_AcChrgCmplSts_Enum <-> outer port CtAp_ChrMgmt/RTE_P_ChrMgmt_AcChrgCmplSts_Enum
    delegate CtAp_ChrgEgyCal.RTE_P_ChrMgmt_BattSideSngChrgEgy_kWh <-> outer port CtAp_ChrMgmt/RTE_P_ChrMgmt_BattSideSngChrgEgy_kWh
    delegate CtAp_ChrgEgyCal.RTE_P_ChrMgmt_ChrgPwr_kW <-> outer port CtAp_ChrMgmt/RTE_P_ChrMgmt_ChrgPwr_kW
    delegate CtAp_ChrgStat.RTE_P_ChrMgmt_ChrgSts_Enum <-> outer port CtAp_ChrMgmt/RTE_P_ChrMgmt_ChrgSts_Enum
    delegate CtAp_ChrgStat.RTE_P_ChrMgmt_ChrgStsErrDTC_8bit <-> outer port CtAp_ChrMgmt/RTE_P_ChrMgmt_ChrgStsErrDTC_8bit
    delegate CtAp_ChrgSdl.RTE_P_ChrMgmt_ChrgTim_min <-> outer port CtAp_ChrMgmt/RTE_P_ChrMgmt_ChrgTim_min
    delegate CtAp_ChrgStat.RTE_P_ChrMgmt_DcChrgAllwd_Flg <-> outer port CtAp_ChrMgmt/RTE_P_ChrMgmt_DcChrgAllwd_Flg
    delegate CtAp_ChrgStat.RTE_P_ChrMgmt_DcChrgCmplSts_Enum <-> outer port CtAp_ChrMgmt/RTE_P_ChrMgmt_DcChrgCmplSts_Enum
    delegate CtAp_ChrgEgyCal.RTE_P_ChrMgmt_DcChrgrSideSngChrgEgy_kWh <-> outer port CtAp_ChrMgmt/RTE_P_ChrMgmt_DcChrgrSideSngChrgEgy_kWh
    delegate CtAp_ChrgStat.RTE_P_ChrMgmt_KeepWrm_Flg <-> outer port CtAp_ChrMgmt/RTE_P_ChrMgmt_KeepWrm_Flg
    delegate CtAp_ChrgPreHeat.RTE_P_ChrMgmt_NegRlyOpenReq_Flg <-> outer port CtAp_ChrMgmt/RTE_P_ChrMgmt_NegRlyOpenReq_Flg
    delegate CtAp_ChrgStat.RTE_P_ChrMgmt_OBCCtrlMdlSts_Enum <-> outer port CtAp_ChrMgmt/RTE_P_ChrMgmt_OBCCtrlMdlSts_Enum
    delegate CtAp_ChrgStat.RTE_P_ChrMgmt_OBCEnaAllwd_Flg <-> outer port CtAp_ChrMgmt/RTE_P_ChrMgmt_OBCEnaAllwd_Flg
    delegate CtAp_ChrgEgyCal.RTE_P_ChrMgmt_OBCSideSngChrgEgy_kWh <-> outer port CtAp_ChrMgmt/RTE_P_ChrMgmt_OBCSideSngChrgEgy_kWh
    delegate CtAp_ChrgEgyCal.RTE_P_ChrMgmt_OBCSideSngDchaEgy_kWh <-> outer port CtAp_ChrMgmt/RTE_P_ChrMgmt_OBCSideSngDchaEgy_kWh
    delegate CtAp_ChrgStat.RTE_P_ChrMgmt_PlugSts_Enum <-> outer port CtAp_ChrMgmt/RTE_P_ChrMgmt_PlugSts_Enum
    delegate CtAp_ChrgEgyCal.RTE_P_ChrMgmt_PODSideSngChrgEgy_kWh <-> outer port CtAp_ChrMgmt/RTE_P_ChrMgmt_PODSideSngChrgEgy_kWh
    delegate CtAp_ChrgPreHeat.RTE_P_ChrMgmt_PreheatPODDiReq_Flg <-> outer port CtAp_ChrMgmt/RTE_P_ChrMgmt_PreheatPODDiReq_Flg
    delegate CtAp_ChrgPreHeat.RTE_P_ChrMgmt_PreheatSts_Enum <-> outer port CtAp_ChrMgmt/RTE_P_ChrMgmt_PreheatSts_Enum
    delegate CtAp_ChrgStat.RTE_P_ChrMgmt_ReqHvRdy_Flg <-> outer port CtAp_ChrMgmt/RTE_P_ChrMgmt_ReqHvRdy_Flg
    delegate CtAp_ChrgEgyCal.RTE_P_ChrMgmt_VCUCalcdPODIDc_A <-> outer port CtAp_ChrMgmt/RTE_P_ChrMgmt_VCUCalcdPODIDc_A
    delegate CtAp_ChrgEgyCal.RTE_P_ChrMgmt_VCUDispChrgI_A <-> outer port CtAp_ChrMgmt/RTE_P_ChrMgmt_VCUDispChrgI_A
    delegate CtAp_ChrgEgyCal.RTE_P_ChrMgmt_VCUDispChrgU_V <-> outer port CtAp_ChrMgmt/RTE_P_ChrMgmt_VCUDispChrgU_V
    delegate CtAp_ChrgEgyCal.RTE_R_ComM_AcChrgPha_Enum <-> outer port CtAp_ChrMgmt/RTE_R_ComM_AcChrgPha_Enum
    delegate CtAp_ChrgStat.RTE_R_ComM_ApptChrgMdlSts_Enum <-> outer port CtAp_ChrMgmt/RTE_R_ComM_ApptChrgMdlSts_Enum
    delegate CtAp_ChrgSdl.RTE_R_ComM_BattMaxTemp_C <-> outer port CtAp_ChrMgmt/RTE_R_ComM_BattMaxTemp_C
    delegate CtAp_ChrgSdl.RTE_R_ComM_BattMinTemp_C <-> outer port CtAp_ChrMgmt/RTE_R_ComM_BattMinTemp_C
    delegate CtAp_ChrgSdl.RTE_R_ComM_BMSBattDispSOC_pct <-> outer port CtAp_ChrMgmt/RTE_R_ComM_BMSBattDispSOC_pct
    delegate CtAp_ChrgStat.RTE_R_ComM_BMSBattDispSOC_pct <-> outer port CtAp_ChrMgmt/RTE_R_ComM_BMSBattDispSOC_pct
    delegate CtAp_ChrgEgyCal.RTE_R_ComM_BMSBattIDc_A <-> outer port CtAp_ChrMgmt/RTE_R_ComM_BMSBattIDc_A
    delegate CtAp_ChrgPreHeat.RTE_R_ComM_BMSBattIDc_A <-> outer port CtAp_ChrMgmt/RTE_R_ComM_BMSBattIDc_A
    delegate CtAp_ChrgEgyCal.RTE_R_ComM_BMSBattLnkUDc_V <-> outer port CtAp_ChrMgmt/RTE_R_ComM_BMSBattLnkUDc_V
    delegate CtAp_ChrgPreHeat.RTE_R_ComM_BMSBattPckUDc_V <-> outer port CtAp_ChrMgmt/RTE_R_ComM_BMSBattPckUDc_V
    delegate CtAp_ChrgSdl.RTE_R_ComM_BMSBattRateCp_Ah <-> outer port CtAp_ChrMgmt/RTE_R_ComM_BMSBattRateCp_Ah
    delegate CtAp_ChrgEgyCal.RTE_R_ComM_BMSBattUDc_V <-> outer port CtAp_ChrMgmt/RTE_R_ComM_BMSBattUDc_V
    delegate CtAp_ChrgStat.RTE_R_ComM_BMSChrgCmplSts_Enum <-> outer port CtAp_ChrMgmt/RTE_R_ComM_BMSChrgCmplSts_Enum
    delegate CtAp_ChrgStat.RTE_R_ComM_BMSChrgReqSts_Enum <-> outer port CtAp_ChrMgmt/RTE_R_ComM_BMSChrgReqSts_Enum
    delegate CtAp_ChrgPreHeat.RTE_R_ComM_BMSChrgSts_Enum <-> outer port CtAp_ChrMgmt/RTE_R_ComM_BMSChrgSts_Enum
    delegate CtAp_ChrgStat.RTE_R_ComM_BMSChrgSts_Enum <-> outer port CtAp_ChrMgmt/RTE_R_ComM_BMSChrgSts_Enum
    delegate CtAp_ChrgStat.RTE_R_ComM_BMSKeepWrmReq_Enum <-> outer port CtAp_ChrMgmt/RTE_R_ComM_BMSKeepWrmReq_Enum
    delegate CtAp_ChrgSdl.RTE_R_ComM_BMSRemnChrgTim_min <-> outer port CtAp_ChrMgmt/RTE_R_ComM_BMSRemnChrgTim_min
    delegate CtAp_ChrgEgyCal.RTE_R_ComM_CCSOutpIDc_A <-> outer port CtAp_ChrMgmt/RTE_R_ComM_CCSOutpIDc_A
    delegate CtAp_ChrgEgyCal.RTE_R_ComM_CCSOutpUDc_V <-> outer port CtAp_ChrMgmt/RTE_R_ComM_CCSOutpUDc_V
    delegate CtAp_ChrgSdl.RTE_R_ComM_CMLMaxOutpIDc_A <-> outer port CtAp_ChrMgmt/RTE_R_ComM_CMLMaxOutpIDc_A
    delegate CtAp_ChrgStat.RTE_R_ComM_DchaSwtSts_Enum <-> outer port CtAp_ChrMgmt/RTE_R_ComM_DchaSwtSts_Enum
    delegate CtAp_ChrgStat.RTE_R_ComM_IVIChrgCmd_Enum <-> outer port CtAp_ChrMgmt/RTE_R_ComM_IVIChrgCmd_Enum
    delegate CtAp_ChrgStat.RTE_R_ComM_MaxChrgSOCSet_Enum <-> outer port CtAp_ChrMgmt/RTE_R_ComM_MaxChrgSOCSet_Enum
    delegate CtAp_ChrgStat.RTE_R_ComM_MinDchaSOCSet_Enum <-> outer port CtAp_ChrMgmt/RTE_R_ComM_MinDchaSOCSet_Enum
    delegate CtAp_ChrgStat.RTE_R_ComM_OBCCCSts_Enum <-> outer port CtAp_ChrMgmt/RTE_R_ComM_OBCCCSts_Enum
    delegate CtAp_ChrgStat.RTE_R_ComM_OBCCPSts_Enum <-> outer port CtAp_ChrMgmt/RTE_R_ComM_OBCCPSts_Enum
    delegate CtAp_ChrgEgyCal.RTE_R_ComM_OBCInpIAc_A <-> outer port CtAp_ChrMgmt/RTE_R_ComM_OBCInpIAc_A
    delegate CtAp_ChrgEgyCal.RTE_R_ComM_OBCInpUAc_V <-> outer port CtAp_ChrMgmt/RTE_R_ComM_OBCInpUAc_V
    delegate CtAp_ChrgEgyCal.RTE_R_ComM_OBCOutpIDc_A <-> outer port CtAp_ChrMgmt/RTE_R_ComM_OBCOutpIDc_A
    delegate CtAp_ChrgStat.RTE_R_ComM_OBCOutpIDc_A <-> outer port CtAp_ChrMgmt/RTE_R_ComM_OBCOutpIDc_A
    delegate CtAp_ChrgEgyCal.RTE_R_ComM_OBCOutpUDc_V <-> outer port CtAp_ChrMgmt/RTE_R_ComM_OBCOutpUDc_V
    delegate CtAp_ChrgPreHeat.RTE_R_ComM_OBCOutpUDc_V <-> outer port CtAp_ChrMgmt/RTE_R_ComM_OBCOutpUDc_V
    delegate CtAp_ChrgStat.RTE_R_ComM_PEPSPwrMod_Enum <-> outer port CtAp_ChrMgmt/RTE_R_ComM_PEPSPwrMod_Enum
    delegate CtAp_ChrgEgyCal.RTE_R_ComM_PODDCFCUDc_V <-> outer port CtAp_ChrMgmt/RTE_R_ComM_PODDCFCUDc_V
    delegate CtAp_ChrgPreHeat.RTE_R_ComM_PODDCFCUDc_V <-> outer port CtAp_ChrMgmt/RTE_R_ComM_PODDCFCUDc_V
    delegate CtAp_ChrgStat.RTE_R_ComM_SGWChrgCmd_Enum <-> outer port CtAp_ChrMgmt/RTE_R_ComM_SGWChrgCmd_Enum
    delegate CtAp_ChrgPreHeat.RTE_R_ComM_SysIRVal_kOhm <-> outer port CtAp_ChrMgmt/RTE_R_ComM_SysIRVal_kOhm
    delegate CtAp_ChrgSdl.RTE_R_DCChrMgmt_DcChrgnMod_Enum <-> outer port CtAp_ChrMgmt/RTE_R_DCChrMgmt_DcChrgnMod_Enum
    delegate CtAp_ChrgPreHeat.RTE_R_DCChrMgmt_DcChrgnSts_Enum <-> outer port CtAp_ChrMgmt/RTE_R_DCChrMgmt_DcChrgnSts_Enum
    delegate CtAp_ChrgStat.RTE_R_DCChrMgmt_DcChrgnSts_Enum <-> outer port CtAp_ChrMgmt/RTE_R_DCChrMgmt_DcChrgnSts_Enum
    delegate CtAp_ChrgSdl.RTE_R_EgyMgmt_BattChrgIDcLmt_A <-> outer port CtAp_ChrMgmt/RTE_R_EgyMgmt_BattChrgIDcLmt_A
    delegate CtAp_ChrgEgyCal.RTE_R_EgyMgmt_DCDCPwrCnsCalcn_Kw <-> outer port CtAp_ChrMgmt/RTE_R_EgyMgmt_DCDCPwrCnsCalcn_Kw
    delegate CtAp_ChrgEgyCal.RTE_R_EgyMgmt_PackPTCPwrCnsCalcn_Kw <-> outer port CtAp_ChrMgmt/RTE_R_EgyMgmt_PackPTCPwrCnsCalcn_Kw
    delegate CtAp_ChrgEgyCal.RTE_R_EgyMgmt_TCUPwrCnsCalcn_Kw <-> outer port CtAp_ChrMgmt/RTE_R_EgyMgmt_TCUPwrCnsCalcn_Kw
    delegate CtAp_ChrgStat.RTE_R_ErrMgmt_ChrgCtrl_8bit <-> outer port CtAp_ChrMgmt/RTE_R_ErrMgmt_ChrgCtrl_8bit
    delegate CtAp_ChrgStat.RTE_R_GearMgmt_ActGear_Enum <-> outer port CtAp_ChrMgmt/RTE_R_GearMgmt_ActGear_Enum
    delegate CtAp_ChrgPreHeat.RTE_R_HvMgmt_DCDCWrkModActSts_Enum <-> outer port CtAp_ChrMgmt/RTE_R_HvMgmt_DCDCWrkModActSts_Enum
    delegate CtAp_ChrgStat.RTE_R_HvMgmt_DCDCWrkModActSts_Enum <-> outer port CtAp_ChrMgmt/RTE_R_HvMgmt_DCDCWrkModActSts_Enum
    delegate CtAp_ChrgStat.RTE_R_IOAbs_CC2SigUDc_mV <-> outer port CtAp_ChrMgmt/RTE_R_IOAbs_CC2SigUDc_mV
    delegate CtAp_ChrgPreHeat.RTE_R_ModMgmt_HvSts_Enum <-> outer port CtAp_ChrMgmt/RTE_R_ModMgmt_HvSts_Enum
    delegate CtAp_ChrgStat.RTE_R_ModMgmt_HvSts_Enum <-> outer port CtAp_ChrMgmt/RTE_R_ModMgmt_HvSts_Enum
    delegate CtAp_ChrgPreHeat.RTE_R_OBCMgmt_AcChrgnSts_Enum <-> outer port CtAp_ChrMgmt/RTE_R_OBCMgmt_AcChrgnSts_Enum
    delegate CtAp_ChrgStat.RTE_R_OBCMgmt_AcChrgnSts_Enum <-> outer port CtAp_ChrMgmt/RTE_R_OBCMgmt_AcChrgnSts_Enum
    delegate CtAp_ChrgSdl.RTE_R_OBCMgmt_OBCOutpCpbyIDc_A <-> outer port CtAp_ChrMgmt/RTE_R_OBCMgmt_OBCOutpCpbyIDc_A
    delegate CtAp_ChrgStat.RTE_R_VehMot_VehSpd_kph <-> outer port CtAp_ChrMgmt/RTE_R_VehMot_VehSpd_kph
  4 x swc implementation:
    CtAp_ChrgEgyCal_Implementation: behavior=CtAp_ChrgEgyCal_InternalBehavior
      code-descriptors:
        code Default: artifact-descriptors=autosar-engineering-object={short-label=Default, category=SWOBJ}
    CtAp_ChrgPreHeat_Implementation: behavior=CtAp_ChrgPreHeat_InternalBehavior
      code-descriptors:
        code Default: artifact-descriptors=autosar-engineering-object={short-label=Default, category=SWOBJ}
    CtAp_ChrgSdl_Implementation: behavior=CtAp_ChrgSdl_InternalBehavior
      code-descriptors:
        code Default: artifact-descriptors=autosar-engineering-object={short-label=Default, category=SWOBJ}
    CtAp_ChrgStat_Implementation: behavior=CtAp_ChrgStat_InternalBehavior
      code-descriptors:
        code Default: artifact-descriptors=autosar-engineering-object={short-label=Default, category=SWOBJ}
package /PortInterfaces
  72 x sender receiver interface:
    IF_ChgMgmt_ChrgIndcnSts_Enum: invalidation-policy{data-element=tec_ChgMgmt_ChrgIndcnSts_Enum, handle-invalid=DONT-INVALIDATE}
      data tec_ChgMgmt_ChrgIndcnSts_Enum: type=uint8
    IF_ChgMgmt_DchaAbortRsn_Enum: invalidation-policy{data-element=tec_ChgMgmt_DchaAbortRsn_Enum, handle-invalid=DONT-INVALIDATE}
      data tec_ChgMgmt_DchaAbortRsn_Enum: type=uint8
    IF_ChrgMgmt_ChrgnRemnTim_min: invalidation-policy{data-element=tec_ChrgMgmt_ChrgnRemnTim_min, handle-invalid=DONT-INVALIDATE}
      data tec_ChrgMgmt_ChrgnRemnTim_min: type=uint16
    IF_ChrMgmt_AcChrgCmplSts_Enum: invalidation-policy{data-element=tec_ChrMgmt_AcChrgCmplSts_Enum, handle-invalid=DONT-INVALIDATE}
      data tec_ChrMgmt_AcChrgCmplSts_Enum: type=uint8
    IF_ChrMgmt_BattSideSngChrgEgy_kWh: invalidation-policy{data-element=tec_ChrMgmt_BattSideSngChrgEgy_kWh, handle-invalid=DONT-INVALIDATE}
      data tec_ChrMgmt_BattSideSngChrgEgy_kWh: type=float32
    IF_ChrMgmt_ChrgPwr_kW: invalidation-policy{data-element=tec_ChrMgmt_ChrgPwr_kW, handle-invalid=DONT-INVALIDATE}
      data tec_ChrMgmt_ChrgPwr_kW: type=float32
    IF_ChrMgmt_ChrgSts_Enum: invalidation-policy{data-element=tec_ChrMgmt_ChrgSts_Enum, handle-invalid=DONT-INVALIDATE}
      data tec_ChrMgmt_ChrgSts_Enum: type=uint8
    IF_ChrMgmt_ChrgStsErrDTC_8bit: invalidation-policy{data-element=tec_ChrMgmt_ChrgStsErrDTC_8bit, handle-invalid=DONT-INVALIDATE}
      data tec_ChrMgmt_ChrgStsErrDTC_8bit: type=uint8
    IF_ChrMgmt_ChrgTim_min: invalidation-policy{data-element=tec_ChrMgmt_ChrgTim_min, handle-invalid=DONT-INVALIDATE}
      data tec_ChrMgmt_ChrgTim_min: type=uint16
    IF_ChrMgmt_DcChrgAllwd_Flg: invalidation-policy{data-element=tec_ChrMgmt_DcChrgAllwd_Flg, handle-invalid=DONT-INVALIDATE}
      data tec_ChrMgmt_DcChrgAllwd_Flg: type=boolean
    IF_ChrMgmt_DcChrgCmplSts_Enum: invalidation-policy{data-element=tec_ChrMgmt_DcChrgCmplSts_Enum, handle-invalid=DONT-INVALIDATE}
      data tec_ChrMgmt_DcChrgCmplSts_Enum: type=uint8
    IF_ChrMgmt_DcChrgrSideSngChrgEgy_kWh: invalidation-policy{data-element=tec_ChrMgmt_DcChrgrSideSngChrgEgy_kWh, handle-invalid=DONT-INVALIDATE}
      data tec_ChrMgmt_DcChrgrSideSngChrgEgy_kWh: type=float32
    IF_ChrMgmt_KeepWrm_Flg: invalidation-policy{data-element=tec_ChrMgmt_KeepWrm_Flg, handle-invalid=DONT-INVALIDATE}
      data tec_ChrMgmt_KeepWrm_Flg: type=boolean
    IF_ChrMgmt_NegRlyOpenReq_Flg: invalidation-policy{data-element=tec_ChrMgmt_NegRlyOpenReq_Flg, handle-invalid=DONT-INVALIDATE}
      data tec_ChrMgmt_NegRlyOpenReq_Flg: type=boolean
    IF_ChrMgmt_OBCCtrlMdlSts_Enum: invalidation-policy{data-element=tec_ChrMgmt_OBCCtrlMdlSts_Enum, handle-invalid=DONT-INVALIDATE}
      data tec_ChrMgmt_OBCCtrlMdlSts_Enum: type=uint8
    IF_ChrMgmt_OBCEnaAllwd_Flg: invalidation-policy{data-element=tec_ChrMgmt_OBCEnaAllwd_Flg, handle-invalid=DONT-INVALIDATE}
      data tec_ChrMgmt_OBCEnaAllwd_Flg: type=boolean
    IF_ChrMgmt_OBCSideSngChrgEgy_kWh: invalidation-policy{data-element=tec_ChrMgmt_OBCSideSngChrgEgy_kWh, handle-invalid=DONT-INVALIDATE}
      data tec_ChrMgmt_OBCSideSngChrgEgy_kWh: type=float32
    IF_ChrMgmt_OBCSideSngDchaEgy_kWh: invalidation-policy{data-element=tec_ChrMgmt_OBCSideSngDchaEgy_kWh, handle-invalid=DONT-INVALIDATE}
      data tec_ChrMgmt_OBCSideSngDchaEgy_kWh: type=float32
    IF_ChrMgmt_PlugSts_Enum: invalidation-policy{data-element=tec_ChrMgmt_PlugSts_Enum, handle-invalid=DONT-INVALIDATE}
      data tec_ChrMgmt_PlugSts_Enum: type=uint8
    IF_ChrMgmt_PODSideSngChrgEgy_kWh: invalidation-policy{data-element=tec_ChrMgmt_PODSideSngChrgEgy_kWh, handle-invalid=DONT-INVALIDATE}
      data tec_ChrMgmt_PODSideSngChrgEgy_kWh: type=float32
    IF_ChrMgmt_PreheatPODDiReq_Flg: invalidation-policy{data-element=tec_ChrMgmt_PreheatPODDiReq_Flg, handle-invalid=DONT-INVALIDATE}
      data tec_ChrMgmt_PreheatPODDiReq_Flg: type=boolean
    IF_ChrMgmt_PreheatSts_Enum: invalidation-policy{data-element=tec_ChrMgmt_PreheatSts_Enum, handle-invalid=DONT-INVALIDATE}
      data tec_ChrMgmt_PreheatSts_Enum: type=uint8
    IF_ChrMgmt_ReqHvRdy_Flg: invalidation-policy{data-element=tec_ChrMgmt_ReqHvRdy_Flg, handle-invalid=DONT-INVALIDATE}
      data tec_ChrMgmt_ReqHvRdy_Flg: type=boolean
    IF_ChrMgmt_VCUCalcdPODIDc_A: invalidation-policy{data-element=tec_ChrMgmt_VCUCalcdPODIDc_A, handle-invalid=DONT-INVALIDATE}
      data tec_ChrMgmt_VCUCalcdPODIDc_A: type=float32
    IF_ChrMgmt_VCUDispChrgI_A: invalidation-policy{data-element=tec_ChrMgmt_VCUDispChrgI_A, handle-invalid=DONT-INVALIDATE}
      data tec_ChrMgmt_VCUDispChrgI_A: type=float32
    IF_ChrMgmt_VCUDispChrgU_V: invalidation-policy{data-element=tec_ChrMgmt_VCUDispChrgU_V, handle-invalid=DONT-INVALIDATE}
      data tec_ChrMgmt_VCUDispChrgU_V: type=float32
    IF_ComM_AcChrgPha_Enum: invalidation-policy{data-element=tec_ComM_AcChrgPha_Enum, handle-invalid=DONT-INVALIDATE}
      data tec_ComM_AcChrgPha_Enum: type=uint8
    IF_ComM_ApptChrgMdlSts_Enum: invalidation-policy{data-element=tec_ComM_ApptChrgMdlSts_Enum, handle-invalid=DONT-INVALIDATE}
      data tec_ComM_ApptChrgMdlSts_Enum: type=uint8
    IF_ComM_BattMaxTemp_C: invalidation-policy{data-element=tec_ComM_BMSBattMaxTemp_C, handle-invalid=DONT-INVALIDATE}
      data tec_ComM_BMSBattMaxTemp_C: type=sint8
    IF_ComM_BattMinTemp_C: invalidation-policy{data-element=tec_ComM_BMSBattMinTemp_C, handle-invalid=DONT-INVALIDATE}
      data tec_ComM_BMSBattMinTemp_C: type=sint8
    IF_ComM_BMSBattDispSOC_pct: invalidation-policy{data-element=tec_ComM_BMSBattDispSOC_pct, handle-invalid=DONT-INVALIDATE}
      data tec_ComM_BMSBattDispSOC_pct: type=float32
    IF_ComM_BMSBattIDc_A: invalidation-policy{data-element=tec_ComM_BMSBattIDc_A, handle-invalid=DONT-INVALIDATE}
      data tec_ComM_BMSBattIDc_A: type=float32
    IF_ComM_BMSBattLnkUDc_V: invalidation-policy{data-element=tec_ComM_BMSBattLnkUDc_V, handle-invalid=DONT-INVALIDATE}
      data tec_ComM_BMSBattLnkUDc_V: type=float32
    IF_ComM_BMSBattPckUDc_V: invalidation-policy{data-element=tec_ComM_BMSBattPckUDc_V, handle-invalid=DONT-INVALIDATE}
      data tec_ComM_BMSBattPckUDc_V: type=float32
    IF_ComM_BMSBattRateCp_Ah: invalidation-policy{data-element=tec_ComM_BMSBattRateCp_Ah, handle-invalid=DONT-INVALIDATE}
      data tec_ComM_BMSBattRateCp_Ah: type=float32
    IF_ComM_BMSBattUDc_V: invalidation-policy{data-element=tec_ComM_BMSBattUDc_V, handle-invalid=DONT-INVALIDATE}
      data tec_ComM_BMSBattUDc_V: type=float32
    IF_ComM_BMSChrgCmplSts_Enum: invalidation-policy{data-element=tec_ComM_BMSChrgCmplSts_Enum, handle-invalid=DONT-INVALIDATE}
      data tec_ComM_BMSChrgCmplSts_Enum: type=uint8
    IF_ComM_BMSChrgReqSts_Enum: invalidation-policy{data-element=tec_ComM_BMSChrgReqSts_Enum, handle-invalid=DONT-INVALIDATE}
      data tec_ComM_BMSChrgReqSts_Enum: type=uint8
    IF_ComM_BMSChrgSts_Enum: invalidation-policy{data-element=tec_ComM_BMSChrgSts_Enum, handle-invalid=DONT-INVALIDATE}
      data tec_ComM_BMSChrgSts_Enum: type=uint8
    IF_ComM_BMSKeepWrmReq_Enum: invalidation-policy{data-element=tec_ComM_BMSKeepWrmReq_Enum, handle-invalid=DONT-INVALIDATE}
      data tec_ComM_BMSKeepWrmReq_Enum: type=uint8
    IF_ComM_BMSRemnChrgTim_min: invalidation-policy{data-element=tec_ComM_BMSRemnChrgTim_min, handle-invalid=DONT-INVALIDATE}
      data tec_ComM_BMSRemnChrgTim_min: type=uint16
    IF_ComM_CCSOutpIDc_A: invalidation-policy{data-element=tec_ComM_CCSOutpIDc_A, handle-invalid=DONT-INVALIDATE}
      data tec_ComM_CCSOutpIDc_A: type=float32
    IF_ComM_CCSOutpUDc_V: invalidation-policy{data-element=tec_ComM_CCSOutpUDc_V, handle-invalid=DONT-INVALIDATE}
      data tec_ComM_CCSOutpUDc_V: type=float32
    IF_ComM_CMLMaxOutpIDc_A: invalidation-policy{data-element=tec_ComM_CMLMaxOutpIDc_A, handle-invalid=DONT-INVALIDATE}
      data tec_ComM_CMLMaxOutpIDc_A: type=float32
    IF_ComM_DchaSwtSts_Enum: invalidation-policy{data-element=tec_ComM_DchaSwtSts_Enum, handle-invalid=DONT-INVALIDATE}
      data tec_ComM_DchaSwtSts_Enum: type=uint8
    IF_ComM_IVIChrgCmd_Enum: invalidation-policy{data-element=tec_ComM_IVIChrgCmd_Enum, handle-invalid=DONT-INVALIDATE}
      data tec_ComM_IVIChrgCmd_Enum: type=uint8
    IF_ComM_MaxChrgSOCSet_Enum: invalidation-policy{data-element=tec_ComM_MaxChrgSOCSet_Enum, handle-invalid=DONT-INVALIDATE}
      data tec_ComM_MaxChrgSOCSet_Enum: type=uint8
    IF_ComM_MinDchaSOCSet_Enum: invalidation-policy{data-element=tec_ComM_MinDchaSOCSet_Enum, handle-invalid=DONT-INVALIDATE}
      data tec_ComM_MinDchaSOCSet_Enum: type=uint8
    IF_ComM_OBCCCSts_Enum: invalidation-policy{data-element=tec_ComM_OBCCCSts_Enum, handle-invalid=DONT-INVALIDATE}
      data tec_ComM_OBCCCSts_Enum: type=uint8
    IF_ComM_OBCCPSts_Enum: invalidation-policy{data-element=tec_ComM_OBCCPSts_Enum, handle-invalid=DONT-INVALIDATE}
      data tec_ComM_OBCCPSts_Enum: type=uint8
    IF_ComM_OBCInpIAc_A: invalidation-policy{data-element=tec_ComM_OBCInpIAc_A, handle-invalid=DONT-INVALIDATE}
      data tec_ComM_OBCInpIAc_A: type=float32
    IF_ComM_OBCInpUAc_V: invalidation-policy{data-element=tec_ComM_OBCInpUAc_V, handle-invalid=DONT-INVALIDATE}
      data tec_ComM_OBCInpUAc_V: type=float32
    IF_ComM_OBCOutpIDc_A: invalidation-policy{data-element=tec_ComM_OBCOutpIDc_A, handle-invalid=DONT-INVALIDATE}
      data tec_ComM_OBCOutpIDc_A: type=float32
    IF_ComM_OBCOutpUDc_V: invalidation-policy{data-element=tec_ComM_OBCOutpUDc_V, handle-invalid=DONT-INVALIDATE}
      data tec_ComM_OBCOutpUDc_V: type=float32
    IF_ComM_PEPSPwrMod_Enum: invalidation-policy{data-element=tec_ComM_PEPSPwrMod_Enum, handle-invalid=DONT-INVALIDATE}
      data tec_ComM_PEPSPwrMod_Enum: type=uint8
    IF_ComM_PODDCFCUDc_V: invalidation-policy{data-element=tec_ComM_PODDCFCUDc_V, handle-invalid=DONT-INVALIDATE}
      data tec_ComM_PODDCFCUDc_V: type=float32
    IF_ComM_SGWChrgCmd_Enum: invalidation-policy{data-element=tec_ComM_SGWChrgCmd_Enum, handle-invalid=DONT-INVALIDATE}
      data tec_ComM_SGWChrgCmd_Enum: type=uint8
    IF_ComM_SysIRVal_kOhm: invalidation-policy{data-element=tec_ComM_SysIRVal_kOhm, handle-invalid=DONT-INVALIDATE}
      data tec_ComM_SysIRVal_kOhm: type=uint16
    IF_DCChrMgmt_DcChrgnMod_Enum: invalidation-policy{data-element=tec_DCChrMgmt_DcChrgnMod_Enum, handle-invalid=DONT-INVALIDATE}
      data tec_DCChrMgmt_DcChrgnMod_Enum: type=uint8
    IF_DCChrMgmt_DcChrgnSts_Enum: invalidation-policy{data-element=tec_DCChrMgmt_DcChrgnSts_Enum, handle-invalid=DONT-INVALIDATE}
      data tec_DCChrMgmt_DcChrgnSts_Enum: type=uint8
    IF_EgyMgmt_BattChrgIDcLmt_A: invalidation-policy{data-element=tec_EgyMgmt_BattChrgIDcLmt_A, handle-invalid=DONT-INVALIDATE}
      data tec_EgyMgmt_BattChrgIDcLmt_A: type=float32
    IF_EgyMgmt_DCDCPwrCnsCalcn_Kw: invalidation-policy{data-element=tec_EgyMgmt_DCDCPwrCnsCalcn_Kw, handle-invalid=DONT-INVALIDATE}
      data tec_EgyMgmt_DCDCPwrCnsCalcn_Kw: type=float32
    IF_EgyMgmt_PackPTCPwrCnsCalcn_Kw: invalidation-policy{data-element=tec_EgyMgmt_PackPTCPwrCnsCalcn_Kw, handle-invalid=DONT-INVALIDATE}
      data tec_EgyMgmt_PackPTCPwrCnsCalcn_Kw: type=float32
    IF_EgyMgmt_TCUPwrCnsCalcn_Kw: invalidation-policy{data-element=tec_EgyMgmt_TCUPwrCnsCalcn_Kw, handle-invalid=DONT-INVALIDATE}
      data tec_EgyMgmt_TCUPwrCnsCalcn_Kw: type=float32
    IF_ErrMgmt_ChrgCtrl_8bit: invalidation-policy{data-element=tec_ErrMgmt_ChrgCtrl_8bit, handle-invalid=DONT-INVALIDATE}
      data tec_ErrMgmt_ChrgCtrl_8bit: type=uint8
    IF_GearMgmt_ActGear_Enum: invalidation-policy{data-element=tec_GearMgmt_ActGear_Enum, handle-invalid=DONT-INVALIDATE}
      data tec_GearMgmt_ActGear_Enum: type=uint8
    IF_HvMgmt_DCDCWrkModActSts_Enum: invalidation-policy{data-element=tec_HvMgmt_DCDCWrkModActSts_Enum, handle-invalid=DONT-INVALIDATE}
      data tec_HvMgmt_DCDCWrkModActSts_Enum: type=uint8
    IF_IOAbs_CC2SigUDc_mV: invalidation-policy{data-element=tec_IOAbs_CC2SigUDc_mV, handle-invalid=DONT-INVALIDATE}
      data tec_IOAbs_CC2SigUDc_mV: type=uint16
    IF_ModMgmt_HvSts_Enum: invalidation-policy{data-element=tec_ModMgmt_HvSts_Enum, handle-invalid=DONT-INVALIDATE}
      data tec_ModMgmt_HvSts_Enum: type=uint8
    IF_OBCMgmt_AcChrgnSts_Enum: invalidation-policy{data-element=tec_OBCMgmt_AcChrgnSts_Enum, handle-invalid=DONT-INVALIDATE}
      data tec_OBCMgmt_AcChrgnSts_Enum: type=uint8
    IF_OBCMgmt_OBCOutpCpbyIDc_A: invalidation-policy{data-element=tec_OBCMgmt_OBCOutpCpbyIDc_A, handle-invalid=DONT-INVALIDATE}
      data tec_OBCMgmt_OBCOutpCpbyIDc_A: type=float32
    IF_VehMot_VehSpd_kph: invalidation-policy{data-element=tec_VehMot_VehSpd_kph, handle-invalid=DONT-INVALIDATE}
      data tec_VehMot_VehSpd_kph: type=float32
